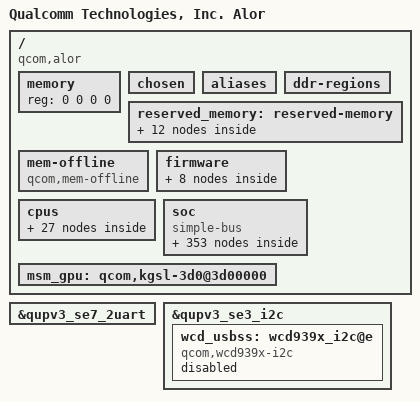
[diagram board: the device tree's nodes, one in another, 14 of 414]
// SPDX-License-Identifier: BSD-3-Clause
/*
 * Copyright (c) Qualcomm Technologies, Inc. and/or its subsidiaries.
 */

#include <dt-bindings/arm/msm/qti-smmu-proxy-dt-ids.h>
#include <dt-bindings/clock/qcom,cambistmclkcc-canoe.h>
#include <dt-bindings/clock/qcom,alor-camcc.h>
#include <dt-bindings/clock/qcom,dispcc-canoe.h>
#include <dt-bindings/clock/qcom,evacc-canoe.h>
#include <dt-bindings/clock/qcom,alor-gcc.h>
#include <dt-bindings/clock/qcom,gpucc-canoe.h>
#include <dt-bindings/clock/qcom,gxclkctl-canoe.h>
#include <dt-bindings/clock/qcom,tcsrcc-canoe.h>
#include <dt-bindings/clock/qcom,videocc-canoe.h>
#include <dt-bindings/clock/qcom,rpmh.h>
#include <dt-bindings/interrupt-controller/arm-gic.h>
#include <dt-bindings/soc/qcom,rpmh-rsc.h>
#include <dt-bindings/interconnect/qcom,icc.h>
#include <dt-bindings/interconnect/qcom,alor.h>
#include <dt-bindings/soc/qcom,ipcc.h>
#include <dt-bindings/mailbox/qcom-ipcc-canoe.h>
#include <dt-bindings/spmi/spmi.h>
#include <dt-bindings/gpio/gpio.h>
#include <dt-bindings/regulator/qcom,rpmh-regulator-levels.h>

/ {
	model = "Qualcomm Technologies, Inc. Alor";
	compatible = "qcom,alor";
	qcom,msm-id = <685 0x10000>;
	interrupt-parent = <&intc>;

	#address-cells = <2>;
	#size-cells = <2>;
	memory { device_type = "memory"; reg = <0 0 0 0>; };


	chosen: chosen {
		bootargs = "loglevel=6 kpti=0 loop.max_part=7 log_buf_len=512K kernel.panic_on_rcu_stall=1 msm_rtb.filter=0x237 rcupdate.rcu_expedited=1 rcu_nocbs=0-7 ftrace_dump_on_oops cpufreq.default_governor=performance printk.console_no_auto_verbose=1 irqaffinity=0-1 swiotlb=0 kasan=off cgroup_disable=pressure cgroup.memory=nokmem,nosocket disable_dma32=on page_poison=on restrict_cma_redirect=false fw_devlink.strict=1 kasan=off can.stats_timer=0 android_arch_task_struct_size=512 pcie_ports=compat sysctl.kernel.sched_pelt_multiplier=4 no-steal-acc pci-msm-drv.pcie_sm_regs=0x1D07000,0x1040,0x1048,0x3000,0x1 androidboot.usbcontroller=a600000.dwc3";
		stdout-path = "/soc/qcom,qupv3_1_geni_se@ac0000/qcom,qup_uart@a9c000:115200n8";
	};

	aliases: aliases {
		mmc1 = &sdhc_2; /* SDC2 SD card slot */
		serial0 = &qupv3_se7_2uart;
		ufshc1 = &ufshc_mem;
		hsuart0 = &qupv3_se14_4uart;
		i2c0 = &qupv3_se0_i2c;
		i2c1 = &qupv3_se1_i2c;
		i2c2 = &qupv3_se2_i2c;
		i2c3 = &qupv3_se3_i2c;
		i2c4 = &qupv3_se4_i2c;
		i2c6 = &qupv3_se6_i2c;
		i2c8 = &qupv3_se8_i2c;
		i2c9 = &qupv3_se9_i2c;
		i2c10 = &qupv3_se10_i2c;
		i2c11 = &qupv3_se11_i2c;
		i2c12 = &qupv3_se12_i2c;
		i2c13 = &qupv3_se13_i2c;
		i2c15 = &qupv3_se15_i2c;
		i2c16 = &qupv3_se16_i2c;
		i2c17 = &qupv3_se17_i2c;
		i2c18 = &qupv3_se18_i2c;
		i2c19 = &qupv3_se19_i2c;
		i2c20 = &qupv3_se20_i2c;
		spi0 = &qupv3_se0_spi;
		spi1 = &qupv3_se1_spi;
		spi2 = &qupv3_se2_spi;
		spi3 = &qupv3_se3_spi;
		spi4 = &qupv3_se4_spi;
		spi6 = &qupv3_se6_spi;
		spi8 = &qupv3_se8_spi;
		spi9 = &qupv3_se9_spi;
		spi10 = &qupv3_se10_spi;
		spi11 = &qupv3_se11_spi;
		spi12 = &qupv3_se12_spi;
		spi13 = &qupv3_se13_spi;
		spi15 = &qupv3_se15_spi;
		spi16 = &qupv3_se16_spi;
		spi17 = &qupv3_se17_spi;
		spi18 = &qupv3_se18_spi;
		spi19 = &qupv3_se19_spi;
		spi20 = &qupv3_se20_spi;
	};

	ddr-regions { };

	reserved_memory: reserved-memory { };

	mem-offline {
		compatible = "qcom,mem-offline";
		offline-sizes = <0x2 0xc0000000 0x1 0x0>;
		granule = <512>;
		qcom,qmp = <&aoss_qmp>;
	};

	firmware: firmware {
		qcom_scm: qcom_scm { };
	};

	cpus {
		#address-cells = <2>;
		#size-cells = <0>;

		CPU0: cpu@0 {
			device_type = "cpu";
			compatible = "arm,armv8";
			reg = <0x0 0x0>;
			enable-method = "psci";
			cpu-idle-states = <&MEDIUM_OFF_C4>;
			power-domains = <&CPU_PD0>;
			power-domain-names = "psci";
			#cooling-cells = <2>;
			clocks = <&pdp_scmi_perf 0>;
			capacity-dmips-mhz = <1024>;
			dynamic-power-coefficient = <100>;
			next-level-cache = <&L2_0>;
			L2_0: l2-cache {
				compatible = "cache";
				cache-level = <2>;
			};
		};

		CPU1: cpu@100 {
			device_type = "cpu";
			compatible = "arm,armv8";
			reg = <0x0 0x100>;
			enable-method = "psci";
			cpu-idle-states = <&MEDIUM_OFF_C4>;
			power-domains = <&CPU_PD1>;
			power-domain-names = "psci";
			#cooling-cells = <2>;
			clocks = <&pdp_scmi_perf 0>;
			capacity-dmips-mhz = <1024>;
			dynamic-power-coefficient = <100>;
			next-level-cache = <&L2_0>;
		};

		CPU2: cpu@200 {
			device_type = "cpu";
			compatible = "arm,armv8";
			reg = <0x0 0x200>;
			enable-method = "psci";
			cpu-idle-states = <&MEDIUM_OFF_C4>;
			power-domains = <&CPU_PD2>;
			power-domain-names = "psci";
			#cooling-cells = <2>;
			clocks = <&pdp_scmi_perf 0>;
			capacity-dmips-mhz = <1024>;
			dynamic-power-coefficient = <100>;
			next-level-cache = <&L2_0>;
		};

		CPU3: cpu@300 {
			device_type = "cpu";
			compatible = "arm,armv8";
			reg = <0x0 0x300>;
			enable-method = "psci";
			cpu-idle-states = <&MEDIUM_OFF_C4>;
			power-domains = <&CPU_PD3>;
			power-domain-names = "psci";
			#cooling-cells = <2>;
			clocks = <&pdp_scmi_perf 0>;
			capacity-dmips-mhz = <1024>;
			dynamic-power-coefficient = <100>;
			next-level-cache = <&L2_0>;
		};

		CPU4: cpu@400 {
			device_type = "cpu";
			compatible = "arm,armv8";
			reg = <0x0 0x400>;
			enable-method = "psci";
			cpu-idle-states = <&MEDIUM_OFF_C4>;
			power-domains = <&CPU_PD4>;
			power-domain-names = "psci";
			#cooling-cells = <2>;
			clocks = <&pdp_scmi_perf 0>;
			capacity-dmips-mhz = <1024>;
			dynamic-power-coefficient = <100>;
			next-level-cache = <&L2_0>;
		};

		CPU5: cpu@500 {
			device_type = "cpu";
			compatible = "arm,armv8";
			reg = <0x0 0x500>;
			enable-method = "psci";
			cpu-idle-states = <&MEDIUM_OFF_C4>;
			power-domains = <&CPU_PD5>;
			power-domain-names = "psci";
			#cooling-cells = <2>;
			clocks = <&pdp_scmi_perf 0>;
			capacity-dmips-mhz = <1024>;
			dynamic-power-coefficient = <100>;
			next-level-cache = <&L2_0>;
		};

		CPU6: cpu@10000 {
			device_type = "cpu";
			compatible = "arm,armv8";
			reg = <0x0 0x10000>;
			enable-method = "psci";
			cpu-idle-states = <&LARGE_OFF_C4>;
			power-domains = <&CPU_PD6>;
			power-domain-names = "psci";
			#cooling-cells = <2>;
			clocks = <&pdp_scmi_perf 1>;
			capacity-dmips-mhz = <1208>;
			dynamic-power-coefficient = <271>;
			next-level-cache = <&L2_6>;
			L2_6: l2-cache {
				compatible = "cache";
				cache-level = <2>;
			};
		};

		CPU7: cpu@10100 {
			device_type = "cpu";
			compatible = "arm,armv8";
			reg = <0x0 0x10100>;
			enable-method = "psci";
			cpu-idle-states = <&LARGE_OFF_C4>;
			power-domains = <&CPU_PD7>;
			power-domain-names = "psci";
			#cooling-cells = <2>;
			clocks = <&pdp_scmi_perf 1>;
			capacity-dmips-mhz = <1208>;
			dynamic-power-coefficient = <271>;
			next-level-cache = <&L2_6>;
		};

		cpu-map {
			cluster0 {
				core0 {
					cpu = <&CPU0>;
				};

				core1 {
					cpu = <&CPU1>;
				};

				core2 {
					cpu = <&CPU2>;
				};

				core3 {
					cpu = <&CPU3>;
				};

				core4 {
					cpu = <&CPU4>;
				};

				core5 {
					cpu = <&CPU5>;
				};
			};

			cluster1 {
				core0 {
					cpu = <&CPU6>;
				};

				core1 {
					cpu = <&CPU7>;
				};
			};
		};

		idle-states {
			entry-method = "psci";

			MEDIUM_OFF_C4: medium-cluster0-c4 { /* C4 */
				compatible = "arm,idle-state";
				idle-state-name = "ret";
				entry-latency-us = <93>;
				exit-latency-us = <129>;
				min-residency-us = <560>;
				arm,psci-suspend-param = <0x00000004>;
			};

			LARGE_OFF_C4: large-cluster1-c4 { /* C4 */
				compatible = "arm,idle-state";
				idle-state-name = "ret";
				entry-latency-us = <172>;
				exit-latency-us = <130>;
				min-residency-us = <686>;
				arm,psci-suspend-param = <0x00000004>;
			};

			MEDIUM_CLUSTER_PWR_DN: medium-cluster-cl5 { /* CL5 */
				compatible = "domain-idle-state";
				entry-latency-us = <2150>;
				exit-latency-us = <1983>;
				min-residency-us = <9144>;
				arm,psci-suspend-param = <0x01000054>;
			};

			LARGE_CLUSTER_PWR_DN: large-cluster-cl5 { /* CL5 */
				compatible = "domain-idle-state";
				entry-latency-us = <2150>;
				exit-latency-us = <1983>;
				min-residency-us = <9144>;
				arm,psci-suspend-param = <0x01000054>;
			};

			APSS_OFF: cluster-ss3 { /* SS3 */
				compatible = "domain-idle-state";
				entry-latency-us = <2800>;
				exit-latency-us = <4400>;
				min-residency-us = <10150>;
				arm,psci-suspend-param = <0x0200B354>;
			};
		};
	};

	soc: soc { };
	msm_gpu: qcom,kgsl-3d0@3d00000 { };
};

#include "alor-reserved-memory.dtsi"
#include "msm-arm-smmu-alor.dtsi"
#include "alor-dma-heaps.dtsi"
#include "alor-pcie.dtsi"

&reserved_memory {
	#address-cells = <2>;
	#size-cells = <2>;
	ranges;

	/* global autoconfigured region for contiguous allocations */
	system_cma: linux,cma {
		compatible = "shared-dma-pool";
		alloc-ranges = <0x0 0x00000000 0x0 0xffffffff>;
		reusable;
		alignment = <0x0 0x400000>;
		size = <0x0 0x2400000>;
		linux,cma-default;
	};

	lcp_dare_pool: lcp_dare_region {
		compatible = "shared-dma-pool";
		reg = <0x8 0x80000000 0x0 0x6000000>;
		reusable;
		alignment = <0x0 0x400000>;
	};

	kinfo_mem: debug_kinfo_region {
		alloc-ranges = <0x0 0x00000000 0xffffffff 0xffffffff>;
		size = <0x0 0x1000>;
		no-map;
	};

	va_md_mem: va_md_mem_region {
		compatible = "shared-dma-pool";
		alloc-ranges = <0x0 0x00000000 0x0 0xffffffff>;
		reusable;
		size = <0 0x1000000>;
	};

	ramoops_mem: ramoops-region {
		alloc-ranges = <0x1 0x00000000 0xfffffffe 0xffffffff>;
		size = <0x0 0x200000>;
		no-map;
	};

	adsp_mem_heap: adsp_heap_region {
		compatible = "shared-dma-pool";
		alloc-ranges = <0x0 0x00000000 0x0 0xffffffff>;
		reusable;
		alignment = <0x0 0x400000>;
		size = <0x0 0xC00000>;
	};

	vm_comm_mem: vm_comm_mem_region {
		compatible = "shared-dma-pool";
		alloc-ranges = <0x0 0x00000000 0x0 0xffffffff>;
		reusable;
		alignment = <0x0 0x400000>;
		size = <0x0 0x800000>;
	};

	hwfence_shbuf: hwfence-shmem {
		no-map;
		reg = <0x0 0xd4e23000 0x0 0x2dd000>;
	};

	non_secure_display_memory: non_secure_display_region {
		compatible = "shared-dma-pool";
		reusable;
		alloc-ranges = <0x0 0x00000000 0x0 0xffffffff>;
		size = <0x0 0xc800000>;
		alignment = <0x0 0x400000>;
	};

	/* cdsp eva shared memory */
	cdsp_eva_mem: cdsp_eva_region {
		compatible = "shared-dma-pool";
		alloc-ranges = <0x0 0x00000000 0x0 0xffffffff>;
		reusable;
		alignment = <0x0 0x400000>;
		size = <0x0 0x400000>;
	};

	qseecom_mem: qseecom_region {
		compatible = "shared-dma-pool";
		alloc-ranges = <0x0 0x00000000 0x0 0xffffffff>;
		reusable;
		alignment = <0x0 0x400000>;
		size = <0x0 0x1400000>;
	};

	qseecom_ta_mem: qseecom_ta_region {
		compatible = "shared-dma-pool";
		alloc-ranges = <0x0 0x00000000 0x0 0xffffffff>;
		reusable;
		alignment = <0x0 0x400000>;
		size = <0x0 0x1400000>;
	};
};

&firmware {
	qcom_scm {
		compatible = "qcom,scm";
		qcom,dload-mode = <&tcsr 0x19000>;
	};

	qcom,sps {
		compatible = "qcom,msm-sps-4k";
		qcom,pipe-attr-ee;
	};

	qcom_smcinvoke {
		compatible = "qcom,smcinvoke";
	};

	qcom_mem_object {
		compatible = "qcom,mem-object";
	};

	qtee_shmbridge {
		compatible = "qcom,tee-shared-memory-bridge";
	};

	qcom,hdcp {
		compatible = "qcom,hdcp";
		qcom,use-smcinvoke = <1>;
	};

	qti,smmu-proxy {
		compatible = "smmu-proxy-sender";
	};

	qcom,seccamtest {
		compatible = "qcom,seccamtest";
		qti,smmu-proxy-cb-id = <QTI_SMMU_PROXY_CAMERA_CB>;
	};
};

&soc {
	#address-cells = <2>;
	#size-cells = <2>;
	ranges = <0 0 0 0 0x10 0>;
	compatible = "simple-bus";

	tlmm: pinctrl@f000000 {
		compatible = "qcom,alor-tlmm";
		reg = <0x0 0xf000000 0x0 0x1000000>;
		interrupts = <GIC_SPI 208 IRQ_TYPE_LEVEL_HIGH>;
		gpio-controller;
		#gpio-cells = <2>;
		interrupt-controller;
		#interrupt-cells = <2>;
		wakeup-parent = <&pdc>;
		qcom,gpios-reserved = <36 37 38 39 46 72 73 74 75 148 149 56 57 58 59>;
	};

	slimbam: bamdma@6c04000 {
		compatible = "qcom,bam-v1.7.0";
		reg = <0x0 0x6c04000 0x0 0x20000>, <0x0 0x6c8f000 0x0 0x1000>;
		reg-names = "bam", "bam_remote_mem";
		interrupts = <0 164 IRQ_TYPE_LEVEL_HIGH>;
		num-channels  = <31>;
		#dma-cells = <1>;
		qcom,controlled-remotely;
		qcom,ee = <1>;
		qcom,num-ees = <2>;
	};

	slim_msm: slim@6c40000 {
		compatible = "qcom,slim-ngd-v1.5.0";
		reg = <0x0 0x6c40000 0x0 0x2c000>, <0x0 0x6c8e000 0x0 0x1000>;
		reg-names = "ctrl", "slimbus_remote_mem";
		interrupts = <0 163 IRQ_TYPE_LEVEL_HIGH>;
		dmas = <&slimbam 3>, <&slimbam 4>;
		dma-names = "rx", "tx";
		#address-cells = <1>;
		#size-cells = <0>;
		status = "disabled";
	};

	intc: interrupt-controller@17000000 {
		compatible = "arm,gic-v3";
		#interrupt-cells = <3>;
		interrupt-controller;
		ranges;
		#redistributor-regions = <1>;
		redistributor-stride = <0x0 0x40000>;
		reg = <0x0 0x17000000 0x0 0x10000>,	/* GICD */
		      <0x0 0x17080000 0x0 0x200000>;	/* GICR * 8 */
		interrupts = <GIC_PPI 9 IRQ_TYPE_LEVEL_HIGH>;

		#address-cells = <1>;
		#size-cells = <1>;
		gic_its: msi-controller@17040000 {
		compatible = "arm,gic-v3-its";
			msi-controller;
			#msi-cells = <1>;
			reg = <0x17040000 0x20000>;
		};
	};

	show_resume_irqs@17000000 {
		compatible = "qcom,show-resume-irqs";
		reg = <0x0 0x17000000 0x0 0x10000>;	/* GICD */
	};

	memtimer: timer@17810000 {
		#address-cells = <1>;
		#size-cells = <1>;
		ranges;
		compatible = "arm,armv7-timer-mem";
		reg = <0x0 0x17810000 0x0 0x1000>;
		clock-frequency = <19200000>;

		frame@17811000 {
			frame-number = <0>;
			interrupts = <GIC_SPI 8 IRQ_TYPE_LEVEL_HIGH>,
				     <GIC_SPI 6 IRQ_TYPE_LEVEL_HIGH>;
			reg = <0x17811000 0x1000>,
			      <0x17812000 0x1000>;
		};

		frame@17813000 {
			frame-number = <1>;
			interrupts = <GIC_SPI 9 IRQ_TYPE_LEVEL_HIGH>;
			reg = <0x17813000 0x1000>;
			status = "disabled";
		};

		frame@17815000 {
			frame-number = <2>;
			interrupts = <GIC_SPI 10 IRQ_TYPE_LEVEL_HIGH>;
			reg = <0x17815000 0x1000>;
			status = "disabled";
		};

		frame@17817000 {
			frame-number = <3>;
			interrupts = <GIC_SPI 11 IRQ_TYPE_LEVEL_HIGH>;
			reg = <0x17817000 0x1000>;
			status = "disabled";
		};

		frame@17819000 {
			frame-number = <4>;
			interrupts = <GIC_SPI 12 IRQ_TYPE_LEVEL_HIGH>;
			reg = <0x17819000 0x1000>;
			status = "disabled";
		};

		frame@1781b000 {
			frame-number = <5>;
			interrupts = <GIC_SPI 13 IRQ_TYPE_LEVEL_HIGH>;
			reg = <0x1781b000 0x1000>;
			status = "disabled";
		};

		frame@1781d000 {
			frame-number = <6>;
			interrupts = <GIC_SPI 14 IRQ_TYPE_LEVEL_HIGH>;
			reg = <0x1781d000 0x1000>;
			status = "disabled";
		};
	};

	wdog: qcom,wdt@17600000 {
		compatible = "qcom,msm-watchdog";
		reg = <0x0 0x17600000 0x0 0x1000>;
		reg-names = "wdt-base";
		interrupts = <GIC_SPI 0 IRQ_TYPE_LEVEL_HIGH>,
			     <GIC_SPI 1 IRQ_TYPE_LEVEL_HIGH>;
		qcom,bark-time = <11000>;
		qcom,pet-time = <9360>;
		qcom,ipi-ping;
		qcom,wakeup-enable;
	};

	arch_timer: timer {
		compatible = "arm,armv8-timer";
		interrupts = <GIC_PPI 13 (GIC_CPU_MASK_SIMPLE(8) | IRQ_TYPE_LEVEL_LOW)>,
			     <GIC_PPI 14 (GIC_CPU_MASK_SIMPLE(8) | IRQ_TYPE_LEVEL_LOW)>,
			     <GIC_PPI 11 (GIC_CPU_MASK_SIMPLE(8) | IRQ_TYPE_LEVEL_LOW)>,
			     <GIC_PPI 10 (GIC_CPU_MASK_SIMPLE(8) | IRQ_TYPE_LEVEL_LOW)>;
		clock-frequency = <19200000>;
	};

	pcie_crm_hw_0_bcm_voter: bcm_voter@0 {
		compatible = "qcom,bcm-voter";
		qcom,crm-name = "pcie_crm";
		qcom,crm-client-idx = <0>;
		qcom,crm-pwr-states = <5>;
	};

	disp_crm_hw_0_bcm_voter: bcm_voter@1 {
		compatible = "qcom,bcm-voter";
		qcom,crm-name = "disp_crm";
		qcom,crm-client-idx = <0>;
		qcom,crm-pwr-states = <2>;
	};

	disp_crm_hw_1_bcm_voter: bcm_voter@2 {
		compatible = "qcom,bcm-voter";
		qcom,crm-name = "disp_crm";
		qcom,crm-client-idx = <1>;
		qcom,crm-pwr-states = <2>;
	};

	disp_crm_hw_2_bcm_voter: bcm_voter@3 {
		compatible = "qcom,bcm-voter";
		qcom,crm-name = "disp_crm";
		qcom,crm-client-idx = <2>;
		qcom,crm-pwr-states = <2>;
	};

	disp_crm_hw_3_bcm_voter: bcm_voter@4 {
		compatible = "qcom,bcm-voter";
		qcom,crm-name = "disp_crm";
		qcom,crm-client-idx = <3>;
		qcom,crm-pwr-states = <2>;
	};

	disp_crm_hw_4_bcm_voter: bcm_voter@5 {
		compatible = "qcom,bcm-voter";
		qcom,crm-name = "disp_crm";
		qcom,crm-client-idx = <4>;
		qcom,crm-pwr-states = <2>;
	};

	disp_crm_hw_5_bcm_voter: bcm_voter@6 {
		compatible = "qcom,bcm-voter";
		qcom,crm-name = "disp_crm";
		qcom,crm-client-idx = <5>;
		qcom,crm-pwr-states = <2>;
	};

	disp_crm_hw_6_bcm_voter: bcm_voter@7 {
		compatible = "qcom,bcm-voter";
		qcom,crm-name = "disp_crm";
		qcom,crm-client-idx = <6>;
		qcom,crm-pwr-states = <2>;
	};

	disp_crm_hw_7_bcm_voter: bcm_voter@8 {
		compatible = "qcom,bcm-voter";
		qcom,crm-name = "disp_crm";
		qcom,crm-client-idx = <7>;
		qcom,crm-pwr-states = <2>;
	};

	disp_crm_hw_8_bcm_voter: bcm_voter@9 {
		compatible = "qcom,bcm-voter";
		qcom,crm-name = "disp_crm";
		qcom,crm-client-idx = <8>;
		qcom,crm-pwr-states = <2>;
	};

	disp_crm_sw_0_bcm_voter: bcm_voter@10 {
		compatible = "qcom,bcm-voter";
		qcom,crm-name = "disp_crm";
		qcom,crm-sw-client;
		qcom,crm-client-idx = <1>;
		qcom,crm-pwr-states = <1>;
	};

	clk_virt: interconnect@0 {
		compatible = "qcom,alor-clk_virt";
		#interconnect-cells = <1>;
		qcom,bcm-voter-names = "hlos",
				       "pcie_crm_hw_0";
		qcom,bcm-voters = <&apps_bcm_voter>,
				  <&pcie_crm_hw_0_bcm_voter>;
	};

	mc_virt: interconnect@1 {
		compatible = "qcom,alor-mc_virt";
		#interconnect-cells = <1>;
		qcom,bcm-voter-names = "hlos",
				       "cam_ife_0",
				       "cam_ife_1",
				       "cam_ife_2",
				       "pcie_crm_hw_0",
				       "disp_crm_hw_0",
				       "disp_crm_hw_1",
				       "disp_crm_hw_2",
				       "disp_crm_hw_3",
				       "disp_crm_hw_4",
				       "disp_crm_hw_5",
				       "disp_crm_hw_6",
				       "disp_crm_hw_7",
				       "disp_crm_hw_8",
				       "disp_crm_sw_0";
		qcom,bcm-voters = <&apps_bcm_voter>,
				  <&cam_bcm_voter0>,
				  <&cam_bcm_voter1>,
				  <&cam_bcm_voter2>,
				  <&pcie_crm_hw_0_bcm_voter>,
				  <&disp_crm_hw_0_bcm_voter>,
				  <&disp_crm_hw_1_bcm_voter>,
				  <&disp_crm_hw_2_bcm_voter>,
				  <&disp_crm_hw_3_bcm_voter>,
				  <&disp_crm_hw_4_bcm_voter>,
				  <&disp_crm_hw_5_bcm_voter>,
				  <&disp_crm_hw_6_bcm_voter>,
				  <&disp_crm_hw_7_bcm_voter>,
				  <&disp_crm_hw_8_bcm_voter>,
				  <&disp_crm_sw_0_bcm_voter>;
	};

	aggre1_noc: interconnect@16e0000 {
		compatible = "qcom,alor-aggre1_noc";
		reg = <0x0 0x16e0000 0x0 0x16400>;
		#interconnect-cells = <1>;
		clocks = <&gcc GCC_AGGRE_UFS_PHY_AXI_CLK>,
			 <&gcc GCC_AGGRE_USB3_PRIM_AXI_CLK>;
		qcom,bcm-voter-names = "hlos";
		qcom,bcm-voters = <&apps_bcm_voter>;
	};

	aggre2_noc: interconnect@1700000 {
		compatible = "qcom,alor-aggre2_noc";
		reg = <0x0 0x1700000 0x0 0x22400>;
		#interconnect-cells = <1>;
		clocks = <&rpmhcc RPMH_IPA_CLK>;
		qcom,bcm-voter-names = "hlos";
		qcom,bcm-voters = <&apps_bcm_voter>;
	};

	config_noc: interconnect@1600000 {
		compatible = "qcom,alor-cnoc_cfg";
		reg = <0x0 0x1600000 0x0 0x9200>;
		#interconnect-cells = <1>;
		qcom,bcm-voter-names = "hlos";
		qcom,bcm-voters = <&apps_bcm_voter>;
	};

	cnoc_main: interconnect@1500000 {
		compatible = "qcom,alor-cnoc_main";
		reg = <0x0 0x1500000 0x0 0x1a080>;
		#interconnect-cells = <1>;
		qcom,bcm-voter-names = "hlos";
		qcom,bcm-voters = <&apps_bcm_voter>;
	};

	gem_noc: interconnect@31100000 {
		compatible = "qcom,alor-gem_noc";
		reg = <0x0 0x31100000 0x0 0x153080>;
		#interconnect-cells = <1>;
		qcom,bcm-voter-names = "hlos",
				       "cam_ife_0",
				       "cam_ife_1",
				       "cam_ife_2",
				       "pcie_crm_hw_0",
				       "disp_crm_hw_0",
				       "disp_crm_hw_1",
				       "disp_crm_hw_2",
				       "disp_crm_hw_3",
				       "disp_crm_hw_4",
				       "disp_crm_hw_5",
				       "disp_crm_hw_6",
				       "disp_crm_hw_7",
				       "disp_crm_hw_8",
				       "disp_crm_sw_0";
		qcom,bcm-voters = <&apps_bcm_voter>,
				  <&cam_bcm_voter0>,
				  <&cam_bcm_voter1>,
				  <&cam_bcm_voter2>,
				  <&pcie_crm_hw_0_bcm_voter>,
				  <&disp_crm_hw_0_bcm_voter>,
				  <&disp_crm_hw_1_bcm_voter>,
				  <&disp_crm_hw_2_bcm_voter>,
				  <&disp_crm_hw_3_bcm_voter>,
				  <&disp_crm_hw_4_bcm_voter>,
				  <&disp_crm_hw_5_bcm_voter>,
				  <&disp_crm_hw_6_bcm_voter>,
				  <&disp_crm_hw_7_bcm_voter>,
				  <&disp_crm_hw_8_bcm_voter>,
				  <&disp_crm_sw_0_bcm_voter>;
	};

	lpass_ag_noc: interconnect@7f40000 {
		compatible = "qcom,alor-lpass_ag_noc";
		reg = <0x0 0x7f40000 0x0 0xe080>;
		#interconnect-cells = <1>;
		qcom,bcm-voter-names = "hlos";
		qcom,bcm-voters = <&apps_bcm_voter>;
	};

	lpass_lpiaon_noc: interconnect@7400000 {
		compatible = "qcom,alor-lpass_lpiaon_noc";
		reg = <0x0 0x7400000 0x0 0x19080>;
		#interconnect-cells = <1>;
		qcom,bcm-voter-names = "hlos";
		qcom,bcm-voters = <&apps_bcm_voter>;
	};

	lpass_lpicx_noc: interconnect@7420000 {
		compatible = "qcom,alor-lpass_lpicx_noc";
		reg = <0x0 0x7420000 0x0 0x44080>;
		#interconnect-cells = <1>;
		qcom,bcm-voter-names = "hlos";
		qcom,bcm-voters = <&apps_bcm_voter>;
	};

	mmss_noc: interconnect@1780000 {
		compatible = "qcom,alor-mmss_noc";
		reg = <0x0 0x1780000 0x0 0x7d400>;
		#interconnect-cells = <1>;
		qcom,bcm-voter-names = "hlos",
				       "cam_ife_0",
				       "cam_ife_1",
				       "cam_ife_2",
				       "disp_crm_hw_0",
				       "disp_crm_hw_1",
				       "disp_crm_hw_2",
				       "disp_crm_hw_3",
				       "disp_crm_hw_4",
				       "disp_crm_hw_5",
				       "disp_crm_hw_6",
				       "disp_crm_hw_7",
				       "disp_crm_hw_8",
				       "disp_crm_sw_0";
		qcom,bcm-voters = <&apps_bcm_voter>,
				  <&cam_bcm_voter0>,
				  <&cam_bcm_voter1>,
				  <&cam_bcm_voter2>,
				  <&disp_crm_hw_0_bcm_voter>,
				  <&disp_crm_hw_1_bcm_voter>,
				  <&disp_crm_hw_2_bcm_voter>,
				  <&disp_crm_hw_3_bcm_voter>,
				  <&disp_crm_hw_4_bcm_voter>,
				  <&disp_crm_hw_5_bcm_voter>,
				  <&disp_crm_hw_6_bcm_voter>,
				  <&disp_crm_hw_7_bcm_voter>,
				  <&disp_crm_hw_8_bcm_voter>,
				  <&disp_crm_sw_0_bcm_voter>;
	};

	nsp_noc: interconnect@260c0000 {
		compatible = "qcom,alor-nsp_noc";
		reg = <0x0 0x260c0000 0x0 0x1c080>;
		#interconnect-cells = <1>;
		qcom,bcm-voter-names = "hlos";
		qcom,bcm-voters = <&apps_bcm_voter>;
	};

	pcie_anoc: interconnect@16c0000 {
		compatible = "qcom,alor-pcie_anoc";
		reg = <0x0 0x16c0000 0x0 0x11400>;
		#interconnect-cells = <1>;
		clocks = <&gcc GCC_AGGRE_NOC_PCIE_AXI_CLK>,
			 <&gcc GCC_CFG_NOC_PCIE_ANOC_AHB_CLK>;
		qcom,bcm-voter-names = "hlos",
				       "pcie_crm_hw_0";
		qcom,bcm-voters = <&apps_bcm_voter>,
				  <&pcie_crm_hw_0_bcm_voter>;
	};

	system_noc: interconnect@1680000 {
		compatible = "qcom,alor-system_noc";
		reg = <0x0 0x1680000 0x0 0x1f080>;
		#interconnect-cells = <1>;
		qcom,bcm-voter-names = "hlos";
		qcom,bcm-voters = <&apps_bcm_voter>;
	};

	ipcc_mproc: qcom,ipcc@1106000 {
		compatible = "qcom,ipcc";
		reg = <0x0 0x1106000 0x0 0x1000>;
		interrupts = <GIC_SPI 246 IRQ_TYPE_LEVEL_HIGH>;
		interrupt-controller;
		#interrupt-cells = <3>;
		#mbox-cells = <2>;
	};

	qcom_tzlog: tz-log@14680720 {
		compatible = "qcom,tz-log";
		reg = <0x0 0x14680720 0x0 0x3000>;
		qcom,hyplog-enabled;
		hyplog-address-offset = <0x410>;
		hyplog-size-offset = <0x414>;
		tmecrashdump-address-offset = <0x81CA0000>;
	};

	eud: qcom,msm-eud@88e0000 {
		compatible = "qcom,msm-eud";
		interrupt-names = "eud_irq";
		interrupt-parent = <&pdc>;
		interrupts = <11 IRQ_TYPE_LEVEL_HIGH>;
		reg = <0x0 0x88e0000 0x0 0x2000>,
			<0x0 0x88e2000 0x0 0x1000>;
		reg-names = "eud_base", "eud_mode_mgr2";
		qcom,secure-eud-en;
		qcom,eud-utmi-delay = /bits/ 16 <255>;
		status = "ok";
	};

	cache-controller@31800000 {
		compatible = "qcom,alor-llcc";
		reg = <0x0 0x31800000 0x0 0x200000>, <0x0 0x32800000 0x0 0x200000>,
			<0x0 0x31C00000 0x0 0x200000>, <0x0 0x32C00000 0x0 0x200000>,
			<0x0 0x34800000 0x0 0x200000>, <0x0 0x34C00000 0x0 0x200000>;
		reg-names = "llcc0_base", "llcc1_base", "llcc2_base",
			"llcc3_base", "llcc_broadcast_or_base",
			"llcc_broadcast_and_base";
		interrupts = <GIC_SPI 266 IRQ_TYPE_LEVEL_HIGH>;
		cap-based-alloc-and-pwr-collapse;
	};

	gic-interrupt-router {
		compatible = "qcom,gic-intr-routing";
		/* keep a few m cores in class0 only to avoid wakeup of l cores */
		qcom,gic-class0-cpus = <&CPU0 &CPU1>;
		/* keep other cores in class1 */
		qcom,gic-class1-cpus = <&CPU2 &CPU3 &CPU4 &CPU5 &CPU6 &CPU7>;
		qcom,gic-cpulist = <&CPU0 &CPU1 &CPU2 &CPU3 &CPU4 &CPU5 &CPU6 &CPU7>;
		qcom,gic-runtime-cpu-class-en;
	};

	qcom,secure-buffer {
		compatible = "qcom,secure-buffer";
		qcom,vmid-cp-camera-preview-ro;
	};

	qcom,mem-buf {
		compatible = "qcom,mem-buf";
		qcom,mem-buf-capabilities = "supplier";
		qcom,vmid = <3>;
	};

	qcom,mem-buf-msgq {
		compatible = "qcom,mem-buf-msgq";
		qcom,msgq-names = "trusted_vm", "oem_vm";
	};

	psci {
		compatible = "arm,psci-1.0";
		method = "smc";

		CPU_PD0: cpu-pd0 {
			#power-domain-cells = <0>;
			power-domains = <&CLUSTER_PD0>;
		};

		CPU_PD1: cpu-pd1 {
			#power-domain-cells = <0>;
			power-domains = <&CLUSTER_PD0>;
		};

		CPU_PD2: cpu-pd2 {
			#power-domain-cells = <0>;
			power-domains = <&CLUSTER_PD0>;
		};

		CPU_PD3: cpu-pd3 {
			#power-domain-cells = <0>;
			power-domains = <&CLUSTER_PD0>;
		};

		CPU_PD4: cpu-pd4 {
			#power-domain-cells = <0>;
			power-domains = <&CLUSTER_PD0>;
		};

		CPU_PD5: cpu-pd5 {
			#power-domain-cells = <0>;
			power-domains = <&CLUSTER_PD0>;
		};

		CPU_PD6: cpu-pd6 {
			#power-domain-cells = <0>;
			power-domains = <&CLUSTER_PD1>;
		};

		CPU_PD7: cpu-pd7 {
			#power-domain-cells = <0>;
			power-domains = <&CLUSTER_PD1>;
		};

		CLUSTER_PD0: cluster-pd0 {
			#power-domain-cells = <0>;
			power-domains = <&CLUSTER_PD2>;
			domain-idle-states = <&MEDIUM_CLUSTER_PWR_DN>;
		};

		CLUSTER_PD1: cluster-pd1 {
			#power-domain-cells = <0>;
			power-domains = <&CLUSTER_PD2>;
			domain-idle-states = <&LARGE_CLUSTER_PWR_DN>;
		};

		CLUSTER_PD2: cluster-pd2 {
			#power-domain-cells = <0>;
			domain-idle-states = <&APSS_OFF>;
		};
	};

	disp_crm: crm@9bc3000 {
		label = "disp_crm";
		compatible = "qcom,disp-crm-v3";
		reg = <0x0 0x9bc3000 0x0 0x9000>, <0x0 0x9bcc000 0x0 0x400>, <0x0 0x9bcc400 0x0 0x400>,
		      <0x0 0x9bcc800 0x0 0x2000>, <0x0 0x9bce800 0x0 0x600>, <0x0 0x9bcee00 0x0 0x200>;
		reg-names = "base", "crm_b", "crm_b_pt", "crm_c", "crm_v", "common";
		interrupts = <GIC_SPI 812 IRQ_TYPE_EDGE_RISING>,
			     <GIC_SPI 813 IRQ_TYPE_EDGE_RISING>,
			     <GIC_SPI 814 IRQ_TYPE_EDGE_RISING>,
			     <GIC_SPI 815 IRQ_TYPE_EDGE_RISING>,
			     <GIC_SPI 816 IRQ_TYPE_EDGE_RISING>,
			     <GIC_SPI 817 IRQ_TYPE_EDGE_RISING>;
		interrupt-names = "disp_crm_drv0",
				  "disp_crm_drv1",
				  "disp_crm_drv2",
				  "disp_crm_drv3",
				  "disp_crm_drv4",
				  "disp_crm_drv5";
		clocks = <&dispcc DISP_CC_MDSS_AHB_CLK>;
		qcom,hw-drv-ids = <0 1 2 3 4 5 6 7 8>;
		qcom,sw-drv-ids = <1>;
	};

	cam_crm: crm@9548000 {
		label = "cam_crm";
		compatible = "qcom,cam-crm-v3";
		reg = <0x0 0x9548000 0x0 0x1e00>, <0x0 0x9549e00 0x0 0x400>, <0x0 0x954a200 0x0 0x400>,
		      <0x0 0x954a600 0x0 0x2000>, <0x0 0x954c600 0x0 0x600>, <0x0 0x954cc00 0x0 0x200>;
		reg-names = "base", "crm_b", "crm_b_pt", "crm_c", "crm_v", "common";
		interrupts = <GIC_SPI 121 IRQ_TYPE_EDGE_RISING>;
		interrupt-names = "cam_crm_drv0";
		clocks = <&camcc CAM_CC_DRV_AHB_CLK>;
		qcom,hw-drv-ids = <0 1 2>;
		qcom,sw-drv-ids = <0>;
	};

	pcie_crm: crm@1d01000 {
		label = "pcie_crm";
		compatible = "qcom,pcie-crm-v3";
		reg = <0x0 0x1d01000 0x0 0x2000>, <0x0 0x1d03000 0x0 0x400>, <0x0 0x1d03400 0x0 0x400>,
		      <0x0 0x1d03800 0x0 0x2000>, <0x0 0x1d05800 0x0 0x600>, <0x0 0x1d05e00 0x0 0x200>;
		reg-names = "base", "crm_b", "crm_b_pt", "crm_c", "crm_v", "common";
		interrupts = <GIC_SPI 641 IRQ_TYPE_EDGE_RISING>;
		interrupt-names = "pcie_crm_drv0";
		clocks = <&pcie_0_pipe_clk>;
		qcom,hw-drv-ids = <0 1>;
		qcom,sw-drv-ids = <0>;
	};

	pcie_pdc: pdc@b370000 {
		compatible = "qcom,alor-pcie-pdc", "qcom,pcie-pdc";
		reg = <0x0 0xb370000 0x0 0x10000>;
	};

	google,debug-kinfo {
		compatible = "google,debug-kinfo";
		memory-region = <&kinfo_mem>;
	};

	mini_dump_mode {
		compatible = "qcom,minidump";
		status = "ok";
	};

	va_mini_dump {
		compatible = "qcom,va-minidump";
		memory-region = <&va_md_mem>;
		status = "ok";
	};

	qcom_ramoops {
		compatible = "qcom,ramoops";
		memory-region = <&ramoops_mem>;
		pmsg-size = <0x200000>;
		mem-type = <2>;
	};

	qcom,mpm2-sleep-counter@c221000 {
		compatible = "qcom,mpm2-sleep-counter";
		reg = <0x0 0xc221000 0x0 0x1000>;
		clock-frequency = <32768>;
	};

	tcsr: syscon@1fc0000 {
		compatible = "syscon";
		reg = <0x0 0x1fc0000 0x0 0x30000>;
	};

	tcsr_mutex_block: syscon@1f40000 {
		compatible = "syscon";
		reg = <0x0 0x1f40000 0x0 0x20000>;
	};

	tcsr_mutex: hwlock {
		compatible = "qcom,tcsr-mutex";
		syscon = <&tcsr_mutex_block 0 0x1000>;
		#hwlock-cells = <1>;
	};

	aoss_qmp: power-controller@c300000 {
		compatible = "qcom,aoss-qmp";
		reg = <0x0 0xc300000 0x0 0x400>;
		interrupt-parent = <&ipcc_mproc>;
		interrupts = <IPCC_MPROC_AOP
			      IPCC_MPROC_SIGNAL_GLINK_QMP
			      IRQ_TYPE_EDGE_RISING>;
		mboxes = <&ipcc_mproc IPCC_MPROC_AOP
			  IPCC_MPROC_SIGNAL_GLINK_QMP>;

		#power-domain-cells = <1>;
		#clock-cells = <0>;
	};

	qmp_tme: qcom,qmp-tme {
		compatible = "qcom,qmp-mbox";
		qcom,remote-pid = <14>;
		mboxes = <&ipcc_mproc IPCC_MPROC_TME
			  IPCC_MPROC_SIGNAL_GLINK_QMP>;
		mbox-names = "tme_qmp";
		interrupt-parent = <&ipcc_mproc>;
		interrupts = <IPCC_MPROC_TME
			      IPCC_MPROC_SIGNAL_GLINK_QMP
			      IRQ_TYPE_EDGE_RISING>;

		label = "tme";
		qcom,early-boot;
		priority = <0>;
		mbox-desc-offset = <0x0>;
		#mbox-cells = <1>;
	};

	qcom,tmecom-qmp-client {
		compatible = "qcom,tmecom-qmp-client";
		mboxes = <&qmp_tme 0>;
		mbox-names = "tmecom";
		label = "tmecom";
		depends-on-supply = <&qmp_tme>;
	};

	qcom,smp2p-adsp {
		compatible = "qcom,smp2p";
		qcom,smem = <443>, <429>;
		interrupt-parent = <&ipcc_mproc>;
		interrupts = <IPCC_MPROC_LPASS IPCC_MPROC_SIGNAL_SMP2P
			      IRQ_TYPE_EDGE_RISING>;
		mboxes = <&ipcc_mproc IPCC_MPROC_LPASS
			  IPCC_MPROC_SIGNAL_SMP2P>;
		qcom,local-pid = <0>;
		qcom,remote-pid = <2>;

		adsp_smp2p_out: master-kernel {
			qcom,entry-name = "master-kernel";
			#qcom,smem-state-cells = <1>;
		};

		adsp_smp2p_in: slave-kernel {
			qcom,entry-name = "slave-kernel";
			interrupt-controller;
			#interrupt-cells = <2>;
		};

		sleepstate_smp2p_out: sleepstate-out {
			qcom,entry-name = "sleepstate";
			#qcom,smem-state-cells = <1>;
		};

		sleepstate_smp2p_in: qcom,sleepstate-in {
			qcom,entry-name = "sleepstate_see";
			interrupt-controller;
			#interrupt-cells = <2>;
		};

		smp2p_rdbg2_out: qcom,smp2p-rdbg2-out {
			qcom,entry-name = "rdbg";
			#qcom,smem-state-cells = <1>;
		};

		smp2p_rdbg2_in: qcom,smp2p-rdbg2-in {
			qcom,entry-name = "rdbg";
			interrupt-controller;
			#interrupt-cells = <2>;
		};
	};

	qcom,smp2p-cdsp {
		compatible = "qcom,smp2p";
		qcom,smem = <94>, <432>;
		interrupt-parent = <&ipcc_mproc>;
		interrupts = <IPCC_MPROC_CDSP IPCC_MPROC_SIGNAL_SMP2P
			      IRQ_TYPE_EDGE_RISING>;
		mboxes = <&ipcc_mproc IPCC_MPROC_CDSP IPCC_MPROC_SIGNAL_SMP2P>;
		qcom,local-pid = <0>;
		qcom,remote-pid = <5>;

		cdsp_smp2p_out: master-kernel {
			qcom,entry-name = "master-kernel";
			#qcom,smem-state-cells = <1>;
		};

		cdsp_smp2p_in: slave-kernel {
			qcom,entry-name = "slave-kernel";
			interrupt-controller;
			#interrupt-cells = <2>;
		};

		smp2p_rdbg5_out: qcom,smp2p-rdbg5-out {
			qcom,entry-name = "rdbg";
			#qcom,smem-state-cells = <1>;
		};

		smp2p_rdbg5_in: qcom,smp2p-rdbg5-in {
			qcom,entry-name = "rdbg";
			interrupt-controller;
			#interrupt-cells = <2>;
		};
	};

	qcom,smp2p-modem {
		compatible = "qcom,smp2p";
		qcom,smem = <435>, <428>;
		interrupt-parent = <&ipcc_mproc>;
		interrupts = <IPCC_MPROC_MPSS IPCC_MPROC_SIGNAL_SMP2P
			      IRQ_TYPE_EDGE_RISING>;
		mboxes = <&ipcc_mproc IPCC_MPROC_MPSS IPCC_MPROC_SIGNAL_SMP2P>;
		qcom,local-pid = <0>;
		qcom,remote-pid = <1>;

		modem_smp2p_out: master-kernel {
			qcom,entry-name = "master-kernel";
			#qcom,smem-state-cells = <1>;
		};

		modem_smp2p_in: slave-kernel {
			qcom,entry-name = "slave-kernel";
			interrupt-controller;
			#interrupt-cells = <2>;
		};

		smp2p_ipa_1_out: qcom,smp2p-ipa-1-out {
			qcom,entry-name = "ipa";
			#qcom,smem-state-cells = <1>;
		};

		/* ipa - inbound entry from mss */
		smp2p_ipa_1_in: qcom,smp2p-ipa-1-in {
			qcom,entry-name = "ipa";
			interrupt-controller;
			#interrupt-cells = <2>;
		};

		smp2p_smem_mailbox_1_out: qcom,smp2p-smem-mailbox-1-out {
			qcom,entry-name = "smem-mailbox";
			#qcom,smem-state-cells = <1>;
		};

		smp2p_smem_mailbox_1_in: qcom,smp2p-smem-mailbox-1-in {
			qcom,entry-name = "smem-mailbox";
			interrupt-controller;
			#interrupt-cells = <2>;
		};
	};

	qcom,smp2p-soccp {
		compatible = "qcom,smp2p";
		qcom,smem = <617>, <616>;
		interrupt-parent = <&ipcc_mproc>;
		interrupts = <IPCC_MPROC_SOCCP IPCC_MPROC_SIGNAL_SMP2P
			      IRQ_TYPE_EDGE_RISING>;
		mboxes = <&ipcc_mproc IPCC_MPROC_SOCCP IPCC_MPROC_SIGNAL_SMP2P>;
		qcom,local-pid = <0>;
		qcom,remote-pid = <19>;

		soccp_smp2p_out: master-kernel {
			qcom,entry-name = "master-kernel";
			#qcom,smem-state-cells = <1>;
		};

		soccp_smp2p_in: slave-kernel {
			qcom,entry-name = "slave-kernel";
			interrupt-controller;
			#interrupt-cells = <2>;
		};
	};

	qcom,smp2p-dcp {
		compatible = "qcom,smp2p";
		qcom,smem = <617>, <616>;
		interrupt-parent = <&ipcc_mproc>;
		interrupts = <IPCC_MPROC_DCP IPCC_MPROC_SIGNAL_SMP2P
			      IRQ_TYPE_EDGE_RISING>;
		mboxes = <&ipcc_mproc IPCC_MPROC_DCP IPCC_MPROC_SIGNAL_SMP2P>;
		qcom,local-pid = <0>;
		qcom,remote-pid = <22>;

		dcp_smp2p_out: master-kernel {
			qcom,entry-name = "master-kernel";
			#qcom,smem-state-cells = <1>;
		};

		dcp_smp2p_in: slave-kernel {
			qcom,entry-name = "slave-kernel";
			interrupt-controller;
			#interrupt-cells = <2>;
		};
	};

	qcom,smp2p-wpss {
		compatible = "qcom,smp2p";
		qcom,smem = <617>, <616>;
		interrupt-parent = <&ipcc_mproc>;
		interrupts = <IPCC_MPROC_WPSS IPCC_MPROC_SIGNAL_SMP2P
			      IRQ_TYPE_EDGE_RISING>;
		mboxes = <&ipcc_mproc IPCC_MPROC_WPSS IPCC_MPROC_SIGNAL_SMP2P>;
		qcom,local-pid = <0>;
		qcom,remote-pid = <13>;

		wpss_smp2p_out: master-kernel {
			qcom,entry-name = "master-kernel";
			#qcom,smem-state-cells = <1>;
		};

		wpss_smp2p_in: slave-kernel {
			qcom,entry-name = "slave-kernel";
			interrupt-controller;
			#interrupt-cells = <2>;
		};
	};

	qcom,smp2p_sleepstate {
		compatible = "qcom,smp2p-sleepstate";
		qcom,smem-states = <&sleepstate_smp2p_out 0>;
		interrupt-parent = <&sleepstate_smp2p_in>;
		interrupts = <0 0>;
		interrupt-names = "smp2p-sleepstate-in";
	};

	qcom,msm-imem@14680000 {
		compatible = "qcom,msm-imem";
		reg = <0x0 0x14680000 0x0 0x1000>;
		ranges = <0x0 0x0 0x14680000 0x1000>;
		#address-cells = <1>;
		#size-cells = <1>;

		mem_dump_table@10 {
			compatible = "qcom,msm-imem-mem_dump_table";
			reg = <0x10 0x8>;
		};

		restart_reason@65c {
			compatible = "qcom,msm-imem-restart_reason";
			reg = <0x65c 0x4>;
		};

		dload_type@1c {
			compatible = "qcom,msm-imem-dload-type";
			reg = <0x1c 0x4>;
		};

		boot_stats@6b0 {
			compatible = "qcom,msm-imem-boot_stats";
			reg = <0x6b0 0x20>;
		};

		kaslr_offset@6d0 {
			compatible = "qcom,msm-imem-kaslr_offset";
			reg = <0x6d0 0xc>;
		};

		pil@94c {
			compatible = "qcom,pil-reloc-info";
			reg = <0x94c 0xc8>;
		};

		pil@6dc {
			compatible = "qcom,msm-imem-pil-disable-timeout";
			reg = <0x6dc 0x4>;
		};

		diag_dload@c8 {
			compatible = "qcom,msm-imem-diag-dload";
			reg = <0xc8 0xc8>;
		};

		modem_dsm@c98 {
			compatible = "qcom,msm-imem-mss-dsm";
			reg = <0xc98 0x10>;
		};

		sys_dbg@af8 {
			compatible = "qcom,msm-imem-gpu-dump-skip";
			reg = <0xb0c 0x4>;
		};
	};

	qcom,memshare {
		compatible = "qcom,memshare";

		qcom,client_1 {
			compatible = "qcom,memshare-peripheral";
			qcom,peripheral-size = <0x0>;
			qcom,client-id = <0>;
			qcom,allocate-boot-time;
			label = "modem";
		};

		qcom,client_2 {
			compatible = "qcom,memshare-peripheral";
			qcom,peripheral-size = <0x0>;
			qcom,client-id = <2>;
			label = "modem";
		};

		qcom,client_3 {
			compatible = "qcom,memshare-peripheral";
			qcom,peripheral-size = <0x500000>;
			qcom,client-id = <1>;
			qcom,allocate-on-request;
			label = "modem";
		};

		qcom,client_ims_1 {
			compatible = "qcom,memshare-peripheral";
			qcom,peripheral-size = <0x100000>;
			qcom,client-id = <7>;
			qcom,allocate-on-request;
			qcom,shared;
			label = "modem";
		};

		qcom,client_ims_2 {
			compatible = "qcom,memshare-peripheral";
			qcom,peripheral-size = <0x100000>;
			qcom,client-id = <8>;
			qcom,allocate-on-request;
			qcom,shared;
			label = "modem";
		};
	};

	cpu_pmu: cpu-pmu {
		compatible = "arm,armv8-pmuv3";
		interrupts = <GIC_PPI 7 IRQ_TYPE_LEVEL_HIGH>;
	};

	vendor_hooks: qcom,cpu-vendor-hooks {
		compatible = "qcom,cpu-vendor-hooks";
	};

	logbuf: qcom,logbuf-vendor-hooks {
		compatible = "qcom,logbuf-vendor-hooks";
	};

	qfprom: qfprom@221c8000 {
		compatible = "qcom,alor-qfprom", "qcom,qfprom";
		reg = <0x0 0x221c8000 0x0 0x1000>;
		#address-cells = <1>;
		#size-cells = <1>;
		read-only;
		ranges;
	};

	cnss_audio_iommu_group0: cnss_audio_iommu_group0 {
		qcom,iommu-msi-size = <0x1000>;
		qcom,iommu-geometry = <0x0 0x18000000 0x0 0x98010000>;
		qcom,iommu-dma = "fastmap";
		qcom,iommu-pagetable = "coherent";
		qcom,iommu-faults = "stall-disable", "HUPCF", "non-fatal";
	};

	wpss_pas: remoteproc-wpss@99f00000 {
		compatible = "qcom,alor-wpss-pas";
		reg = <0x0 0x99f00000 0x0 0x10000>;
		status = "ok";

		memory-region = <&wpss_mem>;

		firmware-name = "wcn7750/wpss.mdt";

		clocks = <&rpmhcc RPMH_CXO_CLK>;
		clock-names = "xo";

		cx-supply = <&VDD_CX_LEVEL>;
		cx-uV-uA = <RPMH_REGULATOR_LEVEL_TURBO 100000>;
		mx-supply = <&VDD_MX_LEVEL>;
		mx-uV-uA = <RPMH_REGULATOR_LEVEL_TURBO 100000>;
		reg-names = "cx","mx";

		qcom,qmp = <&aoss_qmp>;

		/* Inputs from wpss */
		interrupts-extended = <&intc GIC_SPI 87 IRQ_TYPE_EDGE_RISING>,
				      <&wpss_smp2p_in 0 0>,
				      <&wpss_smp2p_in 2 0>,
				      <&wpss_smp2p_in 1 0>,
				      <&wpss_smp2p_in 3 0>,
				      <&wpss_smp2p_in 7 0>;

		interrupt-names = "wdog",
				   "fatal",
				   "handover",
				   "ready",
				   "stop-ack",
				   "shutdown-ack";

		/* Outputs to wpss */
		qcom,smem-states = <&wpss_smp2p_out 0>;
		qcom,smem-state-names = "stop";

		glink-edge {
			qcom,remote-pid = <13>;
			transport = "smem";
			mboxes = <&ipcc_mproc IPCC_MPROC_WPSS
				  IPCC_MPROC_SIGNAL_GLINK_QMP>;
			mbox-names = "wpss_smem";
			interrupt-parent = <&ipcc_mproc>;
			interrupts = <IPCC_MPROC_WPSS
					  IPCC_MPROC_SIGNAL_GLINK_QMP
					  IRQ_TYPE_EDGE_RISING>;

			label = "wpss";
			qcom,glink-label = "wpss";

			qcom,wpss_qrtr {
				qcom,glink-channels = "IPCRTR";
				qcom,intents = <0x800  5
						0x2000 3
						0x4400 2>;
			};
		};
	};

	qcom,msm-adsprpc-mem {
		compatible = "qcom,msm-adsprpc-mem-region";
		memory-region = <&adsp_mem_heap>;
		restrict-access;
	};

	clocks {
		xo_board: xo_board {
			compatible = "fixed-clock";
			clock-frequency = <76800000>;
			clock-output-names = "xo_board";
			#clock-cells = <0>;
		};

		sleep_clk: sleep_clk {
			compatible = "fixed-clock";
			clock-frequency = <32000>;
			clock-output-names = "sleep_clk";
			#clock-cells = <0>;
		};

		pcie_0_pipe_clk: pcie_0_pipe_clk {
			compatible = "fixed-clock";
			clock-frequency = <1000>;
			clock-output-names = "pcie_0_pipe_clk";
			#clock-cells = <0>;
		};

		ufs_phy_rx_symbol_0_clk: ufs_phy_rx_symbol_0_clk {
			compatible = "fixed-clock";
			clock-frequency = <1000>;
			clock-output-names = "ufs_phy_rx_symbol_0_clk";
			#clock-cells = <0>;
		};

		ufs_phy_rx_symbol_1_clk: ufs_phy_rx_symbol_1_clk {
			compatible = "fixed-clock";
			clock-frequency = <1000>;
			clock-output-names = "ufs_phy_rx_symbol_1_clk";
			#clock-cells = <0>;
		};

		ufs_phy_tx_symbol_0_clk: ufs_phy_tx_symbol_0_clk {
			compatible = "fixed-clock";
			clock-frequency = <1000>;
			clock-output-names = "ufs_phy_tx_symbol_0_clk";
			#clock-cells = <0>;
		};

		usb3_phy_wrapper_gcc_usb30_pipe_clk: usb3_phy_wrapper_gcc_usb30_pipe_clk {
			compatible = "fixed-clock";
			clock-frequency = <1000>;
			clock-output-names = "usb3_phy_wrapper_gcc_usb30_pipe_clk";
			#clock-cells = <0>;
		};
	};

	cambistmclkcc: clock-controller@1760000 {
		compatible = "qcom,alor-cambistmclkcc", "syscon";
		reg = <0x0 0x1760000 0x0 0x6000>;
		reg-name = "cc_base";
		vdd_mx-supply = <&VDD_MX_LEVEL>;
		clocks = <&rpmhcc RPMH_CXO_CLK>,
			 <&sleep_clk>,
			 <&gcc GCC_CAM_BIST_MCLK_AHB_CLK>;
		clock-names = "bi_tcxo",
			      "sleep_clk",
			      "iface";
		#clock-cells = <1>;
		#reset-cells = <1>;
	};

	camcc_crmc: syscon@954a600 {
		compatible = "syscon";
		reg = <0x0 0x954a600 0x0 0x2000>;
	};

	camcc: clock-controller@956d000 {
		compatible = "qcom,alor-camcc", "syscon";
		reg = <0x0 0x956d000 0x0 0x80000>;
		reg-name = "cc_base";
		vdd_mm-supply = <&VDD_MM_LEVEL>;
		vdd_mx-supply = <&VDD_MX_LEVEL>;
		vdd_mxc-supply = <&VDD_MXC_LEVEL>;
		vdd_mm_mxc_voter-supply = <&VDD_MM_MXC_VOTER_LEVEL>;
		interconnects = <&mmss_noc MASTER_CAMNOC_HF &mc_virt SLAVE_EBI1>;
		interconnect-names = "cam-to-ddr";
		clocks = <&rpmhcc RPMH_CXO_CLK>,
			 <&rpmhcc RPMH_CXO_CLK_A>,
			 <&sleep_clk>,
			 <&gcc GCC_CAMERA_AHB_CLK>;
		clock-names = "bi_tcxo",
			      "bi_tcxo_ao",
			      "sleep_clk",
			      "iface";
		qcom,cam_crm-crmc = <&camcc_crmc>;
		#clock-cells = <1>;
		#reset-cells = <1>;
		#power-domain-cells = <1>;
	};

	dispcc_crm: syscon@9bcc800 {
		compatible = "syscon";
		reg = <0x0 0x9bcc800 0x0 0x2000>;
	};

	dispcc: clock-controller@9ba2000 {
		compatible = "qcom,alor-dispcc", "syscon";
		reg = <0x0 0x9ba2000 0x0 0x20000>;
		reg-name = "cc_base";
		vdd_mm-supply = <&VDD_MM_LEVEL>;
		vdd_mx-supply = <&VDD_MX_LEVEL>;
		clocks = <&rpmhcc RPMH_CXO_CLK>,
			 <&rpmhcc RPMH_CXO_CLK_A>,
			 <&sleep_clk>,
			 <&gcc GCC_DISP_AHB_CLK>;
		clock-names = "bi_tcxo",
			      "bi_tcxo_ao",
			      "sleep_clk",
			      "iface";
		qcom,disp_crm-crmc = <&dispcc_crm>;
		#clock-cells = <1>;
		#power-domain-cells = <1>;
		#reset-cells = <1>;

		dispcc_mx: clock-controller@9ba4000 {
			compatible = "qcom,canoe-dispcc_mx";
			clocks = <&rpmhcc RPMH_CXO_CLK>,
				 <&sleep_clk>;
			clock-names = "bi_tcxo",
				      "sleep_clk";
			#clock-cells = <1>;
		};
	};

	evacc: clock-controller@24f0000 {
		compatible = "qcom,alor-evacc", "syscon";
		reg = <0x0 0x24f0000 0x0 0x10000>;
		reg-name = "cc_base";
		vdd_mm-supply = <&VDD_MM_LEVEL>;
		vdd_mxc-supply = <&VDD_MXC_LEVEL>;
		vdd_mm_mxc_voter-supply = <&VDD_MM_MXC_VOTER_LEVEL>;
		clocks = <&rpmhcc RPMH_CXO_CLK>,
			 <&rpmhcc RPMH_CXO_CLK_A>,
			 <&sleep_clk>,
			 <&gcc GCC_EVA_AHB_CLK>;
		clock-names = "bi_tcxo",
			      "bi_tcxo_ao",
			      "sleep_clk",
			      "iface";
		#clock-cells = <1>;
		#reset-cells = <1>;
		#power-domain-cells = <1>;
	};

	gcc: clock-controller@100000 {
		compatible = "qcom,alor-gcc", "syscon";
		reg = <0x0 0x100000 0x0 0x1f4200>;
		reg-name = "cc_base";
		vdd_cx-supply = <&VDD_CX_LEVEL>;
		vdd_mx-supply = <&VDD_MX_LEVEL>;
		clocks = <&rpmhcc RPMH_CXO_CLK>,
			 <&pcie_0_pipe_clk>,
			 <&sleep_clk>,
			 <&ufs_phy_rx_symbol_0_clk>,
			 <&ufs_phy_rx_symbol_1_clk>,
			 <&ufs_phy_tx_symbol_0_clk>,
			 <&usb3_phy_wrapper_gcc_usb30_pipe_clk>;
		clock-names = "bi_tcxo",
			      "pcie_0_pipe_clk",
			      "sleep_clk",
			      "ufs_phy_rx_symbol_0_clk",
			      "ufs_phy_rx_symbol_1_clk",
			      "ufs_phy_tx_symbol_0_clk",
			      "usb3_phy_wrapper_gcc_usb30_pipe_clk";
		#clock-cells = <1>;
		#reset-cells = <1>;
		#power-domain-cells = <1>;
	};

	gpucc: clock-controller@3d90000 {
		compatible = "qcom,alor-gpucc", "syscon";
		reg = <0x0 0x3d90000 0x0 0x9800>;
		reg-name = "cc_base";
		vdd_cx-supply = <&VDD_CX_LEVEL>;
		vdd_mx-supply = <&VDD_MX_LEVEL>;
		clocks = <&rpmhcc RPMH_CXO_CLK>,
			 <&gcc GCC_GPU_GPLL0_CLK_SRC>,
			 <&gcc GCC_GPU_GPLL0_DIV_CLK_SRC>;
		clock-names = "bi_tcxo",
			      "gpll0_out_main",
			      "gpll0_out_main_div";
		#clock-cells = <1>;
		#reset-cells = <1>;
		#power-domain-cells = <1>;
	};

	gxclkctl: clock-controller@3d68024 {
		compatible = "qcom,canoe-gx_clkctl";
		reg = <0x0 0x3d68024 0x0 0x8>;
		reg-name = "cc_base";
		power-domains = <&gpucc GPU_CC_CX_GDSC>;
		vdd_gfx-supply = <&VDD_GFX_MXC_VOTER_LEVEL>;
		#power-domain-cells = <1>;
	};

	tcsrcc: clock-controller@1fd5044 {
		compatible = "qcom,canoe-tcsrcc", "syscon";
		reg = <0x0 0x1fd5044 0x0 0x1c>;
		reg-name = "cc_base";
		#clock-cells = <1>;
		#reset-cells = <1>;
	};

	videocc: clock-controller@20f0000 {
		compatible = "qcom,alor-videocc", "syscon";
		reg = <0x0 0x20f0000 0x0 0x10000>;
		reg-name = "cc_base";
		vdd_mm-supply = <&VDD_MM_LEVEL>;
		vdd_mxc-supply = <&VDD_MXC_LEVEL>;
		vdd_mm_mxc_voter-supply = <&VDD_MM_MXC_VOTER_LEVEL>;
		clocks = <&rpmhcc RPMH_CXO_CLK>,
			<&rpmhcc RPMH_CXO_CLK_A>,
			<&sleep_clk>,
			<&gcc GCC_VIDEO_AHB_CLK>;
		clock-names = "bi_tcxo",
				"bi_tcxo_ao",
				"sleep_clk",
				"iface";
		#clock-cells = <1>;
		#reset-cells = <1>;
		#power-domain-cells = <1>;
	};

	apsscc: syscon@17c00000 {
		compatible = "syscon";
		reg = <0x0 0x17c00000 0x0 0x8000>;
	};

	gxclkctldebugcc: syscon@3d64000 {
		compatible = "syscon";
		reg = <0x0 0x3d64000 0x0 0x5000>;
	};

	mccc: syscon@310ba000 {
		compatible = "syscon";
		reg = <0x0 0x310ba000 0x0 0x54>;
	};

	debugcc: clock-controller@0 {
		compatible = "qcom,alor-debugcc";
		qcom,apsscc = <&apsscc>;
		qcom,cambistmclkcc = <&cambistmclkcc>;
		qcom,camcc = <&camcc>;
		qcom,dispcc = <&dispcc>;
		qcom,evacc = <&evacc>;
		qcom,gcc = <&gcc>;
		qcom,gpucc = <&gpucc>;
		qcom,gxclkctl = <&gxclkctldebugcc>;
		qcom,videocc = <&videocc>;
		qcom,mccc = <&mccc>;
		clocks = <&rpmhcc RPMH_CXO_CLK>,
			 <&cambistmclkcc 0>,
			 <&camcc 0>,
			 <&dispcc 0>,
			 <&evacc 0>,
			 <&gcc 0>,
			 <&gpucc 0>,
			 <&videocc 0>;
		clock-names = "xo_clk_src",
			      "cambistmclkcc",
			      "camcc",
			      "dispcc",
			      "evacc",
			      "gcc",
			      "gpucc",
			      "videocc";
		#clock-cells = <1>;
	};

	/* GCC GDSCs */
	gcc_usb30_prim_gdsc: qcom,gdsc@139004 {
		compatible = "qcom,gdsc";
		reg = <0x0 0x139004 0x0 0x4>;
		regulator-name = "gcc_usb30_prim_gdsc";
		parent-supply = <&VDD_CX_LEVEL>;
		qcom,retain-regs;
		qcom,support-cfg-gdscr;
		proxy-supply = <&gcc_usb30_prim_gdsc>;
		qcom,proxy-consumer-enable;
	};

	gcc_usb3_phy_gdsc: qcom,gdsc@150018 {
		compatible = "qcom,gdsc";
		reg = <0x0 0x150018 0x0 0x4>;
		regulator-name = "gcc_usb3_phy_gdsc";
		parent-supply = <&VDD_MX_LEVEL>;
		qcom,retain-regs;
		qcom,support-cfg-gdscr;
		proxy-supply = <&gcc_usb3_phy_gdsc>;
		qcom,proxy-consumer-enable;
	};

	apps_rsc: rsc@18900000 {
		label = "apps_rsc";
		compatible = "qcom,rpmh-rsc";
		reg = <0x0 0x18900000 0x0 0x10000>,
		      <0x0 0x18910000 0x0 0x10000>,
		      <0x0 0x18920000 0x0 0x10000>;
		reg-names = "drv-0", "drv-1", "drv-2";
		qcom,drv-count = <3>;
		interrupts = <GIC_SPI 3 IRQ_TYPE_LEVEL_HIGH>,
			     <GIC_SPI 4 IRQ_TYPE_LEVEL_HIGH>,
			     <GIC_SPI 5 IRQ_TYPE_LEVEL_HIGH>;
		power-domains = <&CLUSTER_PD2>;

		apps_rsc_drv2: drv@2 {
			qcom,drv-id = <2>;
			qcom,tcs-offset = <0xd00>;
			qcom,tcs-distance = <0x2a0>;
			channel@0 {
				qcom,tcs-config = <ACTIVE_TCS    3>,
						  <SLEEP_TCS     2>,
						  <WAKE_TCS      2>,
						  <CONTROL_TCS   0>,
						  <FAST_PATH_TCS 1>;
			};

			apps_bcm_voter: bcm_voter {
				compatible = "qcom,bcm-voter";
			};

			rpmhcc: clock-controller {
				compatible = "qcom,alor-rpmh-clk";
				#clock-cells = <1>;
			};

			dcvs_fp: qcom,dcvs-fp {
				compatible = "qcom,dcvs-fp";
				qcom,ddr-bcm-name = "MC4";
				qcom,llcc-bcm-name = "SH5";
			};
		};
	};

	cpucp_sram: cpucp-sram@0x1d838000 {
		#address-cells = <1>;
		#size-cells = <1>;
		compatible = "mmio-sram";
		reg = <0x0 0x1d838000 0x0 0x400>;
		ranges = <0 0x0 0x1d838000 0x400>;

		cpucp_tx: scmi-shmem@0 {
			compatible = "arm,scmi-shmem";
			reg = <0x0 0x200>;
		};

		cpucp_rx: scmi-shmem@1 {
			compatible = "arm,scmi-shmem";
			reg = <0x200 0x200>;
		};
	};

	pdp_sram: pdp-sram@81f08000 {
		#address-cells = <1>;
		#size-cells = <1>;
		compatible = "mmio-sram";
		reg = <0x0 0x81f08000 0x0 0x200>;
		ranges = <0 0x0 0x81f08000 0x200>;

		pdp_rx: scmi-shmem@0 {
			compatible = "arm,scmi-shmem";
			reg = <0x0 0x80>;
		};

		pdp_tx: scmi-shmem@100 {
			compatible = "arm,scmi-shmem";
			reg = <0x100 0x80>;
		};
	};

	cpucp: qcom,cpucp@0x18830000 {
		compatible = "qcom,cpucp-v2";
		reg =	<0x0 0x18830000 0x0 0x300>,
			<0x0 0x17620000 0x0 0x4C08>;
		reg-names = "tx", "rx";
		#mbox-cells = <1>;
		interrupts = <GIC_SPI 28 IRQ_TYPE_LEVEL_HIGH>;
	};

	pdp0: qcom,pdp0@0x19980000 {
		compatible = "qcom,cpucp-v2";
		reg =	<0x0 0x19980000 0x0 0x300>,
			<0x0 0x17610000 0x0 0x4C08>;
		reg-names = "tx", "rx";
		#mbox-cells = <1>;
		interrupts = <GIC_SPI 34 IRQ_TYPE_LEVEL_HIGH>;
		qcom,rx-chans = <0x7>;
	};

	pdp1: qcom,pdp1@0x1a980000 {
		compatible = "qcom,cpucp-v2";
		reg =	<0x0 0x1a980000 0x0 0x300>,
			<0x0 0x17610000 0x0 0x4C08>;
		reg-names = "tx", "rx";
		#mbox-cells = <1>;
		interrupts = <GIC_SPI 34 IRQ_TYPE_LEVEL_HIGH>;
		qcom,rx-chans = <0x8>;
	};

	cpucp_scmi: qcom,cpucp-scmi {
		#address-cells = <1>;
		#size-cells = <0>;
		compatible = "arm,scmi";
		mboxes = <&cpucp 0>, <&cpucp 2>;
		mbox-names = "tx", "rx";
		shmem = <&cpucp_tx>, <&cpucp_rx>;

		cpucp_scmi_clk: protocol@14 {
			reg = <0x14>;
			#clock-cells = <1>;
		};

		cpucp_scmi_qcom: protocol@80 {
			reg = <0x80>;
			#clock-cells = <1>;
		};
	};

	pdp_scmi: qcom,pdp-scmi {
		#address-cells = <1>;
		#size-cells = <0>;
		compatible = "arm,scmi";
		mboxes = <&pdp0 0>, <&pdp0 1>;
		mbox-names = "tx", "rx";
		shmem = <&pdp_tx>, <&pdp_rx>;

		pdp_scmi_perf: protocol@13 {
			reg = <0x13>;
			#clock-cells = <1>;
		};
	};

	cpucp_fast: qcom,cpucp_fast {
		compatible = "qcom,cpucp_fast";
		mboxes = <&cpucp 7>;
		qcom,policy-cpus = < 6 >;
	};

	cpucp_log: qcom,cpucp_log@0x81210000 {
		compatible = "qcom,cpucp-log";
		reg =	<0x0 0x81210000 0x0 0x10000>,
			<0x0 0x81220000 0x0 0x10000>;
		mboxes = <&cpucp 1>;
		qcom,log-type = <0>;
	};

	pdp0_log: qcom,pdp0_log@0x81f4a000 {
		compatible = "qcom,pdp-log";
		reg =	<0x0 0x81f4a000 0x0 0x10000>;
		mboxes = <&pdp0 2>;
		qcom,log-type = <1>;
	};

	pdp1_log: qcom,pdp1_log@0x81f8a000 {
		compatible = "qcom,pdp-log";
		reg =	<0x0 0x81f8a000 0x0 0x10000>;
		mboxes = <&pdp1 3>, <&pdp1 2>;
		qcom,log-type = <2>;
	};

	qcom_mpam: qcom,mpam {
		compatible = "qcom,mpam";
	};

	cpu_mpam: qcom,cpu_mpam {
		compatible = "qcom,cpu-mpam";
		reg = <0x0 0x1d83a000 0x0 0x400>;
		reg-names = "mon-base";

		L2_0 {
			qcom,msc-id = <0>;
			qcom,msc-name = "L2_0";
		};

		L2_1 {
			qcom,msc-id = <1>;
			qcom,msc-name = "L2_1";
		};
	};

	noc_bw_mpam: qcom,noc_bw_mpam {
		compatible = "qcom,platform-mpam";
		reg = <0x0 0x1d83a400 0x0 0x400>;
		reg-names = "mon-base";
		qcom,msc-id = <3>;
		qcom,msc-name = "noc_bw";
		qcom,gears = "low", "medium", "high", "veryhigh";
		qcom,gear-id = <1>, <2>, <3>, <4>;

		cpu_cluster0 {
			qcom,client-id = <0x1>;
			qcom,client-name = "cpu_cluster0";
		};

		cpu_cluster1 {
			qcom,client-id = <0x2>;
			qcom,client-name = "cpu_cluster1";
		};

		gpu {
			qcom,client-id = <0x10>;
			qcom,client-name = "gpu";
		};

		nsp {
			qcom,client-id = <0x100>;
			qcom,client-name = "nsp";
		};
	};

	llcc_pmu: llcc-pmu@0x31095000 {
		compatible = "qcom,llcc-pmu-ver3";
		reg = <0x0 0x31095000 0x0 0x400>;
		reg-names = "lagg-base";
		qcom,idx-tbl =
			< 2 >,
			< 3 >,
			< 4 >,
			< 5 >,
			< 6 >,
			< 7 >,
			< 0 >,
			< 1 >;
	};

	qcom_pmu: qcom,pmu {
		compatible = "qcom,pmu";
		qcom,long-counter;
		qcom,pmu-events-tbl =
			< 0x0008 0xFF 0x02 0x02 >,
			< 0x0011 0xFF 0x01 0x00 >,
			< 0x0017 0xFF 0xFF 0x04 >,
			< 0x1000 0xFF 0xFF 0x08 >;
	};

	ddr_freq_table: ddr-freq-table {
		qcom,freq-tbl =
			<  547000 >,
			< 1353000 >,
			< 1555000 >,
			< 1708000 >,
			< 2092000 >,
			< 2736000 >,
			< 3187000 >,
			< 3686000 >,
			< 4224000 >,
			< 4780000 >;
	};

	llcc_freq_table: llcc-freq-table {
		qcom,freq-tbl =
			<  282000 >,
			<  350000 >,
			<  533000 >,
			<  605600 >,
			<  806000 >,
			<  933000 >,
			< 1066000 >,
			< 1211000 >;
	};

	ddrqos_freq_table: ddrqos-freq-table {
		qcom,freq-tbl =
			< 0 >,
			< 1 >;
	};

	qcom_dcvs: qcom,dcvs {
		compatible = "qcom,dcvs";

		qcom_ddr_dcvs_hw: ddr {
			compatible = "qcom,dcvs-hw";
			qcom,dcvs-hw-type = <0>;
			qcom,bus-width = <4>;
			qcom,freq-tbl = <&ddr_freq_table>;

			ddr_dcvs_sp: sp {
				compatible = "qcom,dcvs-path";
				qcom,dcvs-path-type = <0>;
				interconnects = <&mc_virt MASTER_LLCC
						 &mc_virt SLAVE_EBI1>;
			};

			ddr_dcvs_fp: fp {
				compatible = "qcom,dcvs-path";
				qcom,dcvs-path-type = <1>;
				qcom,fp-voter = <&dcvs_fp>;
			};
		};

		qcom_llcc_dcvs_hw: llcc {
			compatible = "qcom,dcvs-hw";
			qcom,dcvs-hw-type = <1>;
			qcom,bus-width = <16>;
			qcom,freq-tbl = <&llcc_freq_table>;

			llcc_dcvs_sp: sp {
				compatible = "qcom,dcvs-path";
				qcom,dcvs-path-type = <0>;
				interconnects = <&gem_noc MASTER_APPSS_PROC
						 &gem_noc SLAVE_LLCC>;
			};

			llcc_dcvs_fp: fp {
				compatible = "qcom,dcvs-path";
				qcom,dcvs-path-type = <1>;
				qcom,fp-voter = <&dcvs_fp>;
			};
		};

		qcom_ddrqos_dcvs_hw: ddrqos {
			compatible = "qcom,dcvs-hw";
			qcom,dcvs-hw-type = <3>;
			qcom,bus-width = <1>;
			qcom,freq-tbl = <&ddrqos_freq_table>;

			ddrqos_dcvs_sp: sp {
				compatible = "qcom,dcvs-path";
				qcom,dcvs-path-type = <0>;
				interconnects = <&mc_virt MASTER_LLCC
						 &mc_virt SLAVE_EBI1>;
			};
		};
	};

	qcom_memlat: qcom,memlat {
		compatible = "qcom,memlat";

		ddr {
			compatible = "qcom,memlat-grp";
			qcom,target-dev = <&qcom_ddr_dcvs_hw>;
			qcom,sampling-path = <&ddr_dcvs_fp>;
			qcom,miss-ev = <0x1000>;

			gold {
				compatible = "qcom,memlat-mon";
				qcom,cpulist = <&CPU0 &CPU1 &CPU2 &CPU3 &CPU4 &CPU5>;
				qcom,cpufreq-memfreq-tbl =
					<  806400  547000 >,
					< 1036800 1353000 >,
					< 1228800 1555000 >,
					< 1555200 2092000 >,
					< 2611200 3187000 >,
					< 3321600 3686000 >;
				qcom,sampling-enabled;
			};

			prime {
				compatible = "qcom,memlat-mon";
				qcom,cpulist = <&CPU6 &CPU7>;
				qcom,cpufreq-memfreq-tbl =
					<  806400  547000 >,
					<  921600 1353000 >,
					< 1382400 2092000 >,
					< 2112000 3187000 >,
					< 2841600 3686000 >,
					< 3072000 4224000 >,
					< 3430000 4780000 >;
				qcom,sampling-enabled;
			};

			gold-compute {
				compatible = "qcom,memlat-mon";
				qcom,cpulist = <&CPU0 &CPU1 &CPU2 &CPU3 &CPU4 &CPU5 &CPU6 &CPU7>;
				qcom,cpufreq-memfreq-tbl =
					< 1996800  547000 >,
					< 2611200 2092000 >;
				qcom,sampling-enabled;
				qcom,compute-mon;
			};

			prime-latfloor {
				compatible = "qcom,memlat-mon";
				qcom,cpulist = <&CPU6 &CPU7>;
				qcom,cpufreq-memfreq-tbl =
					< 2841600  547000 >,
					< 3072000 4224000 >;
				qcom,sampling-enabled;
			};
		};

		llcc {
			compatible = "qcom,memlat-grp";
			qcom,target-dev = <&qcom_llcc_dcvs_hw>;
			qcom,sampling-path = <&llcc_dcvs_fp>;
			qcom,miss-ev = <0x17>;

			gold {
				compatible = "qcom,memlat-mon";
				qcom,cpulist = <&CPU0 &CPU1 &CPU2 &CPU3 &CPU4 &CPU5>;
				qcom,cpufreq-memfreq-tbl =
					<  806400  282000 >,
					< 1036800  350000 >,
					< 1747200  533000 >,
					< 2611200  806000 >,
					< 3321600  933000 >;
				qcom,sampling-enabled;
			};

			prime {
				compatible = "qcom,memlat-mon";
				qcom,cpulist = <&CPU6 &CPU7>;
				qcom,cpufreq-memfreq-tbl =
					<  806400  282000 >,
					<  921600  350000 >,
					< 1651200  533000 >,
					< 2112000  806000 >,
					< 2841600  933000 >,
					< 3072000 1066000 >,
					< 3430000 1350000 >;
				qcom,sampling-enabled;
			};

			gold-compute {
				compatible = "qcom,memlat-mon";
				qcom,cpulist = <&CPU0 &CPU1 &CPU2 &CPU3 &CPU4 &CPU5 &CPU6 &CPU7>;
				qcom,cpufreq-memfreq-tbl =
					< 1996800  282000 >,
					< 2611200  533000 >;
				qcom,sampling-enabled;
				qcom,compute-mon;
			};
		};

		ddrqos {
			compatible = "qcom,memlat-grp";
			qcom,target-dev = <&qcom_ddrqos_dcvs_hw>;
			qcom,sampling-path = <&ddrqos_dcvs_sp>;
			qcom,miss-ev = <0x1000>;

			ddrqos_gold_lat: gold {
				compatible = "qcom,memlat-mon";
				qcom,cpulist = <&CPU0 &CPU1 &CPU2 &CPU3 &CPU4 &CPU5 &CPU6 &CPU7>;
				qcom,cpufreq-memfreq-tbl =
					< 1900000 0 >,
					< 2800000 1 >;
				qcom,sampling-enabled;
			};

			ddrqos_prime_lat: prime {
				compatible = "qcom,memlat-mon";
				qcom,cpulist = <&CPU6 &CPU7>;
				qcom,cpufreq-memfreq-tbl =
					< 1497000 0 >,
					< 3200000 1 >;
				qcom,sampling-enabled;
			};

			ddrqos_prime_latfloor: prime-latfloor {
				compatible = "qcom,memlat-mon";
				qcom,cpulist = <&CPU6 &CPU7>;
				qcom,cpufreq-memfreq-tbl =
					< 2112000 0 >,
					< 3200000 1 >;
				qcom,sampling-enabled;
			};
		};
	};

	qcom_llcc_ddr_vote: qcom,llcc-ddr-vote {
		qcom,target-dev = <&qcom_ddr_dcvs_hw>;
		qcom,secondary-map =
			<  350000  547000 >,
			<  533000 1555000 >,
			<  605600 2092000 >,
			<  806000 3187000 >,
			<  933000 3686000 >,
			< 1066000 4224000 >,
			< 1211000 4780000 >;
	};

	bwmon_llcc_gold: qcom,bwmon-llcc-gold@310B3300 {
		compatible = "qcom,bwmon4";
		reg = <0x0 0x310B3400 0x0 0x300>, <0x0 0x310B3300 0x0 0x200>;
		reg-names = "base", "global_base";
		interrupts = <GIC_SPI 581 IRQ_TYPE_LEVEL_HIGH>;
		qcom,mport = <0>;
		qcom,hw-timer-hz = <19200000>;
		qcom,count-unit = <0x10000>;
		qcom,target-dev = <&qcom_llcc_dcvs_hw>;
		qcom,second-vote = <&qcom_llcc_ddr_vote>;
	};

	bwmon_llcc_prime: qcom,bwmon-llcc-prime@310B7300 {
		compatible = "qcom,bwmon4";
		reg = <0x0 0x310B7400 0x0 0x300>, <0x0 0x310B7300 0x0 0x200>;
		reg-names = "base", "global_base";
		interrupts = <GIC_SPI 581 IRQ_TYPE_LEVEL_HIGH>;
		qcom,mport = <0>;
		qcom,hw-timer-hz = <19200000>;
		qcom,count-unit = <0x10000>;
		qcom,target-dev = <&qcom_llcc_dcvs_hw>;
		qcom,second-vote = <&qcom_llcc_ddr_vote>;
	};

	bwmon_ddr: qcom,bwmon-ddr@31091000 {
		compatible = "qcom,bwmon5";
		reg = <0x0 0x31091000 0x0 0x1000>;
		reg-names = "base";
		interrupts = <GIC_SPI 81 IRQ_TYPE_LEVEL_HIGH>;
		qcom,hw-timer-hz = <19200000>;
		qcom,count-unit = <0x10000>;
		qcom,target-dev = <&qcom_ddr_dcvs_hw>;
	};

	cam_rsc: rsc@9545000 {
		label = "cam_rsc";
		compatible = "qcom,rpmh-rsc";
		reg = <0x0 0x9545000 0x0 0x1000>,
		      <0x0 0x9546000 0x0 0x1000>,
		      <0x0 0x9547000 0x0 0x1000>;
		reg-names = "drv-0", "drv-1", "drv-2";
		qcom,drv-count = <3>;
		qcom,hw-channel;
		interrupts = <GIC_SPI 368 IRQ_TYPE_LEVEL_HIGH>,
			     <GIC_SPI 369 IRQ_TYPE_LEVEL_HIGH>,
			     <GIC_SPI 370 IRQ_TYPE_LEVEL_HIGH>;

		cam_rsc_drv0: drv@0 {
			qcom,drv-id = <0>;
			qcom,tcs-offset = <0x520>;
			qcom,tcs-distance = <0x150>;
			channel@0 {
				qcom,tcs-config = <ACTIVE_TCS    0>,
						  <WAKE_TCS      1>,
						  <SLEEP_TCS     1>,
						  <CONTROL_TCS   0>,
						  <FAST_PATH_TCS 0>;
			};

			channel@1 {
				qcom,tcs-config = <ACTIVE_TCS    0>,
						  <WAKE_TCS      1>,
						  <SLEEP_TCS     1>,
						  <CONTROL_TCS   0>,
						  <FAST_PATH_TCS 0>;
			};

			cam_bcm_voter0: bcm_voter {
				compatible = "qcom,bcm-voter";
				qcom,no-amc;
			};
		};

		cam_rsc_drv1: drv@1 {
			qcom,drv-id = <1>;
			qcom,tcs-offset = <0x520>;
			qcom,tcs-distance = <0x150>;
			channel@0 {
				qcom,tcs-config = <ACTIVE_TCS    0>,
						  <WAKE_TCS      1>,
						  <SLEEP_TCS     1>,
						  <CONTROL_TCS   0>,
						  <FAST_PATH_TCS 0>;
			};

			channel@1 {
				qcom,tcs-config = <ACTIVE_TCS    0>,
						  <WAKE_TCS      1>,
						  <SLEEP_TCS     1>,
						  <CONTROL_TCS   0>,
						  <FAST_PATH_TCS 0>;
			};

			cam_bcm_voter1: bcm_voter {
				compatible = "qcom,bcm-voter";
				qcom,no-amc;
			};
		};

		cam_rsc_drv2: drv@2 {
			qcom,drv-id = <2>;
			qcom,tcs-offset = <0x520>;
			qcom,tcs-distance = <0x150>;
			channel@0 {
				qcom,tcs-config = <ACTIVE_TCS    0>,
						  <WAKE_TCS      1>,
						  <SLEEP_TCS     1>,
						  <CONTROL_TCS   0>,
						  <FAST_PATH_TCS 0>;
			};

			channel@1 {
				qcom,tcs-config = <ACTIVE_TCS    0>,
						  <WAKE_TCS      1>,
						  <SLEEP_TCS     1>,
						  <CONTROL_TCS   0>,
						  <FAST_PATH_TCS 0>;
			};

			cam_bcm_voter2: bcm_voter {
				compatible = "qcom,bcm-voter";
				qcom,no-amc;
			};
		};
	};

	pdc: interrupt-controller@b220000 {
		compatible = "qcom,alor-pdc", "qcom,pdc";
		reg = <0x0 0xb220000 0x0 0x10000>, <0x0 0x179600f0 0x0 0xf8>;
		qcom,pdc-ranges = <0 745 38>, <40 785 11>, <51 527 4>,
				  <58 534 2>, <61 537 20>, <84 559 14>,
				  <98 609 32>, <130 717 12>, <142 251 5>,
				  <147 796 16>, <163 783 2>, <165 531 2>,
				  <167 536 1>, <168 557 2>, <170 415 1>,
				  <171 438 1>, <172 579 1>, <173 703 1>,
				  <174 708 1>, <175 714 1>, <176 68 1>,
				  <177 86 1>, <178 96 1>, <179 249 1>,
				  <180 504 9>;
		#interrupt-cells = <2>;
		interrupt-parent = <&intc>;
		interrupt-controller;
	};

	qcom,rmtfs_sharedmem@0 {
		compatible = "qcom,sharedmem-uio";
		reg = <0x0 0x0 0x0 0x400000>;
		reg-names = "rmtfs";
		qcom,client-id = <0x00000001>;
	};

	sdhc2_opp_table: sdhc2-opp-table {
		compatible = "operating-points-v2";

		opp-100000000 {
			opp-hz = /bits/ 64 <100000000>;
			opp-peak-kBps = <160000 100000>;
			opp-avg-kBps = <50000 0>;
		};

		opp-202000000 {
			opp-hz = /bits/ 64 <202000000>;
			opp-peak-kBps = <200000 120000>;
			opp-avg-kBps = <104000 0>;
		};
	};


	sdhc_2_dma_resv: sdhc_2_dma_resv_region {
		/*
		 * Restrict IOVA mappings for SDHC2 buffers to the 256 MB region
		 * from 0x40000000 - 0x4fffffff.
		 */
		iommu-addresses = <&sdhc_2 0x0 0x0 0x0 0x40000000>,
				  <&sdhc_2 0x0 0x50000000 0xffffffff 0xb0000000>;
	};

	sdhc_2: sdhci@8804000 {
		compatible = "qcom,sdhci-msm-v5";
		reg = <0x0 0x8804000 0x0 0x1000>;
		reg-names = "hc";

		interrupts = <GIC_SPI 207 IRQ_TYPE_LEVEL_HIGH>,
				<GIC_SPI 223 IRQ_TYPE_LEVEL_HIGH>;
		interrupt-names = "hc_irq", "pwr_irq";

		bus-width = <4>;
		no-sdio;
		no-mmc;
		qcom,restore-after-cx-collapse;
		qcom,uses_level_shifter;

		clocks = <&gcc GCC_SDCC2_AHB_CLK>,
			 <&gcc GCC_SDCC2_APPS_CLK>;
		clock-names = "iface", "core";

		/*
		 * DLL HSR settings. Refer go/hsr - <Target> DLL settings.
		 * Note that the DLL_CONFIG_2 value is not passed from the
		 * device tree, but it is calculated in the driver.
		 */
		qcom,dll-hsr-list = <0x0007442C 0x0 0x10
					0x294106C0 0x80040868>;

		iommus = <&apps_smmu 0x140 0x0>;
		qcom,iommu-dma = "fastmap";
		dma-coherent;
		memory-region = <&sdhc_2_dma_resv>;
		qcom,iommu-geometry = <0x0 0x40000000 0x0 0x10000000>;

		interconnects = <&aggre1_noc MASTER_SDCC_2 &mc_virt SLAVE_EBI1>,
			      <&gem_noc MASTER_APPSS_PROC &config_noc SLAVE_SDCC_2>;
		interconnect-names = "sdhc-ddr", "cpu-sdhc";
		operating-points-v2 = <&sdhc2_opp_table>;

		status = "disabled";

		qos0 {
			mask = <0xf0>;
			vote = <44>;
		};

		qos1 {
			mask = <0x0f>;
			vote = <44>;
		};
	};

	ufsphy_mem: ufsphy_mem@1d80000 {
		reg = <0x0 0x1d80000 0x0 0x2000>;
		reg-names = "phy_mem";
		#phy-cells = <0>;

		power-domains = <&gcc GCC_UFS_MEM_PHY_GDSC>;
		lanes-per-direction = <2>;
		clock-names = "ref_clk_src",
			"ref_aux_clk", "qref_clk",
			"rx_sym0_mux_clk", "rx_sym1_mux_clk", "tx_sym0_mux_clk",
			"rx_sym0_phy_clk", "rx_sym1_phy_clk", "tx_sym0_phy_clk";
		clocks = <&rpmhcc RPMH_CXO_CLK>,
			<&gcc GCC_UFS_PHY_PHY_AUX_CLK>,
			<&tcsrcc TCSR_UFS_CLKREF_EN>,
			<&gcc GCC_UFS_PHY_RX_SYMBOL_0_CLK_SRC>,
			<&gcc GCC_UFS_PHY_RX_SYMBOL_1_CLK_SRC>,
			<&gcc GCC_UFS_PHY_TX_SYMBOL_0_CLK_SRC>,
			<&ufs_phy_rx_symbol_0_clk>,
			<&ufs_phy_rx_symbol_1_clk>,
			<&ufs_phy_tx_symbol_0_clk>;
		resets = <&ufshc_mem 0>;
		status = "disabled";
	};

	ice_cfg: shared_ice {
		alg1 {
			alg-name = "alg1";
			rx-alloc-percent = <60>;
			status = "disabled";
		};

		alg2 {
			alg-name = "alg2";
			status = "disabled";

		};

		alg3 {
			alg-name = "alg3";
			num-core = <28 28 15 13>;
			status = "ok";
		};
	};

	qcom_cedev: qcedev@1de0000 {
		compatible = "qcom,qcedev";
		reg = <0x0 0x1de0000 0x0 0x20000>,
			<0x0 0x1dc4000 0x0 0x22000>;
		reg-names = "crypto-base","crypto-bam-base";
		interrupts = <GIC_SPI 272 IRQ_TYPE_LEVEL_HIGH>,
			<GIC_SPI 274 IRQ_TYPE_EDGE_RISING>;
		interrupt-names = "bam-irq", "core-irq";
		qcom,bam-pipe-pair = <2>;
		qcom,offload-ops-support;
		qcom,use-key-index;
		qcom,bam-pipe-offload-cpb-hlos = <1>;
		qcom,bam-pipe-offload-hlos-cpb = <3>;
		qcom,bam-pipe-offload-hlos-cpb-1 = <8>;
		qcom,bam-pipe-offload-hlos-hlos = <4>;
		qcom,bam-pipe-offload-hlos-hlos-1 = <9>;
		qcom,ce-hw-instance = <0>;
		qcom,ce-device = <0>;
		qcom,ce-hw-shared;
		qcom,bam-ee = <0>;
		qcom,smmu-s1-enable;
		qcom,no-clock-support;
		interconnect-names = "data_path";
		interconnects = <&aggre2_noc MASTER_CRYPTO &mc_virt SLAVE_EBI1>;
		iommus = <&apps_smmu 0x00C0 0x0>,
			<&apps_smmu 0x00C1 0x0>;
		qcom,iommu-dma = "atomic";
		dma-coherent;

		qcom_cedev_ns_cb {
			compatible = "qcom,qcedev,context-bank";
			label = "ns_context";
			iommus = <&apps_smmu 0x00C1 0x0>;
			dma-coherent;
		};

		qcom_cedev_s_cb {
			compatible = "qcom,qcedev,context-bank";
			label = "secure_context";
			iommus = <&apps_smmu 0x00C3 0x0>;
			qcom,iommu-vmid = <0x9>;
			qcom,secure-context-bank;
			dma-noncoherent;
		};
	};

	rng: rng@10c3000 {
		compatible = "qcom,trng";
		reg = <0x0 0x10c3000 0x0 0x1000>;
	};

	ufshc_dma_resv: ufshc_dma_resv_region {
		/*
		 * Restrict IOVA mappings for UFSHC buffers to the 3 GB region
		 * from 0x1000 - 0xffffffff.
		 */
		iommu-addresses = <&ufshc_mem 0x0 0x0 0x0 0x1000>;
	};

	ufshc_opp_table: ufshc-opp-table {
		compatible = "operating-points-v2";
		// LOW_SVS
		opp-100000000 {
			opp-hz = /bits/ 64 <100000000>,
				 /bits/ 64 <0>,
				 /bits/ 64 <0>,
				 /bits/ 64 <100000000>,
				 /bits/ 64 <100000000>,
				 /bits/ 64 <0>,
				 /bits/ 64 <0>,
				 /bits/ 64 <0>,
				 /bits/ 64 <0>;
		};

		// NOM/TURBO
		opp-403000000 {
			opp-hz = /bits/ 64 <403000000>,
				 /bits/ 64 <0>,
				 /bits/ 64 <0>,
				 /bits/ 64 <403000000>,
				 /bits/ 64 <403000000>,
				 /bits/ 64 <0>,
				 /bits/ 64 <0>,
				 /bits/ 64 <0>,
				 /bits/ 64 <0>;
		};
	};

	ufshc_mem: ufshc@1d84000 {
		compatible = "qcom,ufshc";
		reg = <0x0 0x1d84000 0x0 0x3000>,
		      <0x0 0x1d88000 0x0 0x18000>,
		      <0x0 0x1da5000 0x0 0x2000>,
		      <0x0 0x1da4000 0x0 0x10>;
		reg-names = "ufs_mem", "ice", "mcq_sqd", "mcq_vs";

		interrupts = <GIC_SPI 265 IRQ_TYPE_LEVEL_HIGH>;
		phys = <&ufsphy_mem>;
		phy-names = "ufsphy";
		#reset-cells = <1>;

		qcom,ice-use-hwkm;
		power-domains = <&gcc GCC_UFS_PHY_GDSC>;
		lanes-per-direction = <2>;

		qcom,prime-mask = <0xc0>;
		qcom,silver-mask = <0x3f>;
		qcom,cluster-mask = <0x3f 0xc0>;
		/* affine cpu for each CQ starting from CQ:0 to CQ:max_cqs */
		qcom,esi-affinity-mask = <4 5 3 4 5 3 7 7>;

		clock-names =
			"core_clk",
			"bus_aggr_clk",
			"iface_clk",
			"core_clk_unipro",
			"core_clk_ice",
			"ref_clk",
			"tx_lane0_sync_clk",
			"rx_lane0_sync_clk",
			"rx_lane1_sync_clk";
		clocks =
			<&gcc GCC_UFS_PHY_AXI_CLK>,
			<&gcc GCC_AGGRE_UFS_PHY_AXI_CLK>,
			<&gcc GCC_UFS_PHY_AHB_CLK>,
			<&gcc GCC_UFS_PHY_UNIPRO_CORE_CLK>,
			<&gcc GCC_UFS_PHY_ICE_CORE_CLK>,
			<&rpmhcc RPMH_LN_BB_CLK3>,
			<&gcc GCC_UFS_PHY_TX_SYMBOL_0_CLK>,
			<&gcc GCC_UFS_PHY_RX_SYMBOL_0_CLK>,
			<&gcc GCC_UFS_PHY_RX_SYMBOL_1_CLK>;

		operating-points-v2 = <&ufshc_opp_table>;
		interconnects = <&aggre1_noc MASTER_UFS_MEM &mc_virt SLAVE_EBI1>,
				<&gem_noc MASTER_APPSS_PROC &config_noc SLAVE_UFS_MEM_CFG>;
		interconnect-names = "ufs-ddr", "cpu-ufs";

		/* set the dependency that smmu being probed before ufs */
		depends-on-supply = <&apps_smmu>;
		iommus = <&apps_smmu 0x60 0x0>;
		qcom,iommu-dma = "fastmap";
		qcom,iommu-msi-size = <0x1000>;
		msi-parent = <&gic_its 0x60>;
		memory-region = <&ufshc_dma_resv>;
		shared-ice-cfg = <&ice_cfg>;
		dma-coherent;

		reset-gpios = <&tlmm 205 GPIO_ACTIVE_LOW>;
		resets = <&gcc GCC_UFS_PHY_BCR>;
		reset-names = "rst";

		qcom,bypass-pbl-rst-wa;
		qcom,max-cpus = <8>;
		status = "disabled";

		qos0 {
			vote = <44>;
			mask = <0x3f>;
			perf;
		};

		qos1 {
			vote = <44>;
			mask = <0xc0>;
		};
	};

	cpuss-sleep-stats@18870000 {
		compatible = "qcom,cpuss-sleep-stats-v6";
		reg = <0x0 0x18870000 0x0 0x4000>;
		reg-names = "base";
		num-clusters = <2>;
	};

	sys-pm-vx@c320000 {
		compatible = "qcom,sys-pm-violators", "qcom,sys-pm-alor";
		reg = <0x0 0xc320000 0x0 0x400>;
		qcom,qmp = <&aoss_qmp>;
	};

	sram@c3f0000 {
		compatible = "qcom,rpmh-stats-v4";
		reg = <0x0 0xc3f0000 0x0 0x400>;
		qcom,qmp = <&aoss_qmp>;
		ss-name = "modem", "adsp", "adsp_island",
			  "cdsp", "apss", "wpss";
	};

	cluster-device0 {
		compatible = "qcom,lpm-cluster-dev";
		power-domains = <&CLUSTER_PD0>;
		qcom,pred-prem-cnt = <2>;
		qcom,sample-invalid-time = <40000000>;
	};

	cluster-device1 {
		compatible = "qcom,lpm-cluster-dev";
		power-domains = <&CLUSTER_PD1>;
		qcom,pred-prem-cnt = <2>;
		qcom,sample-invalid-time = <40000000>;
		qcom,use-cluster-bias-timer;
	};

	cluster-device2 {
		compatible = "qcom,lpm-cluster-dev";
		power-domains = <&CLUSTER_PD2>;
		qcom,pred-prem-cnt = <2>;
		qcom,sample-invalid-time = <40000000>;
	};

	trust_ui_vm_vblk0_ring: trust_ui_vm_vblk0_ring {
		size = <0x4000>;
		gunyah-label = <0x11>;
	};

	trust_ui_vm_vblk1_ring: trust_ui_vm_vblk1_ring {
		size = <0x4000>;
		gunyah-label = <0x10>;
	};

	trust_ui_vm_swiotlb: trust_ui_vm_swiotlb {
		size = <0x400000>;
		gunyah-label = <0x12>;
	};

	trust_ui_vm: qcom,trust_ui_vm {
		vm_name = "trustedvm";
		shared-buffers-size = <0x408000>;
		shared-buffers = <&trust_ui_vm_vblk0_ring &trust_ui_vm_vblk1_ring &trust_ui_vm_swiotlb>;
	};

	trust_ui_vm_virt_be0: trust_ui_vm_virt_be0@11 {
		qcom,vm = <&trust_ui_vm>;
		qcom,label = <0x11>;
	};

	trust_ui_vm_virt_be1: trust_ui_vm_virt_be1@10 {
		qcom,vm = <&trust_ui_vm>;
		qcom,label = <0x10>;
	};

	gunyah-cma-mem {
		compatible = "gunyah-cma-vm-mem";
		memory-region = <&trust_ui_vm_mem &oem_vm_mem>;
		memory-region-names = "trustedvm_cma" , "oemvm_cma";
	};

	qcom,lcp-dare-dare-pool {
		compatible = "qcom,mem-prot-pool";
		memory-region = <&lcp_dare_pool>;
		qcom,lcp-dare;
	};

	gh_secure_vm_loader0: gh-secure-vm-loader@0 {
		compatible = "qcom,gh-secure-vm-loader";
		qcom,pas-id = <28>;
		qcom,vmid = <45>;
		qcom,firmware-name = "trustedvm";
		qcom,keep-running;
		memory-region = <&trust_ui_vm_mem &vm_comm_mem>;
		virtio-backends = <&trust_ui_vm_virt_be0 &trust_ui_vm_virt_be1>;
	};

	oem_vm_vblk0_ring: oem_vm_vblk0_ring {
		size = <0x4000>;
		gunyah-label = <0x16>; /* persist */
	};

	oem_vm_vblk1_ring: oem_vm_vblk1_ring {
		size = <0x4000>;
		gunyah-label = <0x13>; /* system */
	};

	oem_vm_swiotlb: oem_vm_swiotlb {
		size = <0x100000>;
		gunyah-label = <0x14>;
	};

	oem_vm: qcom,oem_vm {
		vm_name = "oemvm";
		shared-buffers-size = <0x108000>;
		shared-buffers = <&oem_vm_vblk0_ring &oem_vm_vblk1_ring &oem_vm_swiotlb>;
	};

	oem_vm_virt_be0: oem_vm_virt_be0@16 {
		qcom,vm = <&oem_vm>;
		qcom,label = <0x16>; /* persist */
	};

	oem_vm_virt_be1: oem_vm_virt_be1@13 {
		qcom,vm = <&oem_vm>;
		qcom,label = <0x13>; /* system */
	};

	gh_secure_vm_loader1: gh-secure-vm-loader@1 {
		compatible = "qcom,gh-secure-vm-loader";
		qcom,pas-id = <34>;
		qcom,vmid = <49>;
		qcom,firmware-name = "oemvm";
		qcom,keep-running;
		memory-region = <&oem_vm_mem &vm_comm_mem>;
		virtio-backends = <&oem_vm_virt_be0 &oem_vm_virt_be1>;
	};

	qcom,test-dbl-tuivm {
		compatible = "qcom,gh-dbl";
		qcom,label = <0x104>;
	};

	qcom,test-dbl-oemvm {
		compatible = "qcom,gh-dbl";
		qcom,label = <0x105>;
	};

	qcom,test-msgq-tuivm {
		compatible = "qcom,gh-msgq-test";
		gunyah-label = <0x104>;
		qcom,primary;
	};

	qcom,test-msgq-oemvm {
		compatible = "qcom,gh-msgq-test";
		gunyah-label = <0x105>;
		qcom,primary;
	};

	qcom,qrtr-gunyah-tuivm {
		compatible = "qcom,qrtr-gunyah";
		qcom,master;
		gunyah-label = <0x103>;
		peer-name = <2>;
	};

	qcom,gh-qtimer@1781b000 {
		compatible = "qcom,gh-qtmr";
		reg = <0x0 0x1781b000 0x0 0x1000>;
		reg-names = "qtmr-base";
		interrupts = <GIC_SPI 13 IRQ_TYPE_LEVEL_HIGH>;
		interrupt-names = "qcom,qtmr-intr";
		qcom,primary;
	};

	qcom,gunyah-panic-notifier {
		compatible = "qcom,gh-panic-notifier";
		qcom,primary-vm;
		gunyah-label = <0x109>;
		peer-name = <2>;
		memory-region = <&vm_comm_mem>;
		shared-buffer-size = <0x1000>;
	};

	dmesg-dump {
		compatible = "qcom,dmesg-dump";
		qcom,primary-vm;
		gunyah-label = <0x107>;
		peer-name = <2>;
		memory-region = <&vm_comm_mem>;
		shared-buffer-size = <0x1000>;
	};

	tlmm-vm-mem-access {
		compatible = "qcom,tlmm-vm-mem-access";
		qcom,master;

		tuivm {
			qcom,label = <0x08>;
			qcom,vmid = <45>;
			tlmm-vm-gpio-list = <&tlmm 12 0 &tlmm 48 0 &tlmm 49 0 &tlmm 50 0 &tlmm 51 0
					&tlmm 68 0 &tlmm 69 0 &tlmm 70 0 &tlmm 71 0 &tlmm 87 0
					&tlmm 100 0 &tlmm 128 0 &tlmm 146 0 &tlmm 86 0 &tlmm 88 0
					&tlmm 161 0 &tlmm 55 0>;
		};
	};

	tlmm-vm-test {
		compatible = "qcom,tlmm-vm-test";
		qcom,master;
		tlmm-vm-gpio-list = <&tlmm 12 0>;
	};

	adsp_sleepmon: adsp-sleepmon {
		compatible = "qcom,adsp-sleepmon";
		qcom,rproc-handle = <&adsp_pas>;
	};

	qcom,qrtr-mhi-cnss {
		compatible = "qcom,qrtr-mhi";
		qcom,dev-id = <0x1103>;
		qcom,net-id = <0>;
		qcom,low-latency;
	};

	qcom,qrtr-mhi-cnss {
		compatible = "qcom,qrtr-mhi";
		qcom,dev-id = <0x1107>;
		qcom,net-id = <1>;
		qcom,low-latency;
	};

	qcom,qrtr-mhi-cnss {
		compatible = "qcom,qrtr-mhi";
		qcom,dev-id = <0x110E>;
		qcom,net-id = <0>;
		qcom,low-latency;
	};

	modem_pas: remoteproc-mss@04080000 {
		compatible = "qcom,alor-modem-pas";
		reg = <0x0 0x4080000 0x0 0x10000>;
		status = "ok";

		clocks = <&rpmhcc RPMH_CXO_CLK>;
		clock-names = "xo";

		cx-supply = <&VDD_CX_LEVEL>;
		cx-uV-uA = <RPMH_REGULATOR_LEVEL_TURBO 100000>;
		mx-supply = <&VDD_MODEM_LEVEL>;
		mx-uV-uA = <RPMH_REGULATOR_LEVEL_NOM_L1 100000>;
		reg-names = "cx", "mx";

		qcom,qmp = <&aoss_qmp>;

		interconnects = <&mc_virt MASTER_LLCC &mc_virt SLAVE_EBI1>,
				<&aggre2_noc MASTER_CRYPTO &mc_virt SLAVE_EBI1>;
		interconnect-names = "rproc_ddr", "crypto_ddr";

		firmware-name = "modem.mdt", "modem_dtb.mdt";
		memory-region = <&mpss_mem &q6_mpss_dtb_mem &system_cma &dsm_partition_1_mem &dsm_partition_2_mem>;

		/* Inputs from mss */
		interrupts-extended = <&intc GIC_SPI 264 IRQ_TYPE_EDGE_RISING>,
					<&modem_smp2p_in 0 0>,
					<&modem_smp2p_in 2 0>,
					<&modem_smp2p_in 1 0>,
					<&modem_smp2p_in 3 0>,
					<&modem_smp2p_in 7 0>;

		interrupt-names = "wdog",
				"fatal",
				"handover",
				"ready",
				"stop-ack",
				"shutdown-ack";

		/* Outputs to mss */
		qcom,smem-states = <&modem_smp2p_out 0>;
		qcom,smem-state-names = "stop";

		glink-edge {
			qcom,remote-pid = <1>;
			transport = "smem";
			mboxes = <&ipcc_mproc IPCC_MPROC_MPSS
				  IPCC_MPROC_SIGNAL_GLINK_QMP>;
			mbox-names = "mpss_smem";
			interrupt-parent = <&ipcc_mproc>;
			interrupts = <IPCC_MPROC_MPSS
				      IPCC_MPROC_SIGNAL_GLINK_QMP
				      IRQ_TYPE_EDGE_RISING>;

			label = "modem";
			qcom,glink-label = "mpss";

			qcom,modem_qrtr {
				qcom,glink-channels = "IPCRTR";
				qcom,low-latency;
				qcom,intents = <0x800  5
						0x2000 3
						0x4400 2>;
			};

			qcom,modem_ds {
				qcom,glink-channels = "DS";
				qcom,intents = <0x4000 0x2>;
			};
		};
	};

	adsp_pas: remoteproc-adsp@06800000 {
		compatible = "qcom,alor-adsp-pas";
		reg = <0x0 0x06800000 0x0 0x10000>;
		status = "ok";

		cx-supply = <&VDD_LPI_CX_LEVEL>;
		cx-uV-uA = <RPMH_REGULATOR_LEVEL_NOM 0>;
		mx-supply = <&VDD_LPI_MX_LEVEL>;
		mx-uV-uA = <RPMH_REGULATOR_LEVEL_NOM 0>;
		reg-names = "cx", "mx";

		clocks = <&rpmhcc RPMH_CXO_CLK>;
		clock-names = "xo";

		qcom,qmp = <&aoss_qmp>;

		interconnects = <&lpass_lpicx_noc MASTER_LPASS_PROC &mc_virt SLAVE_EBI1>,
				<&aggre2_noc MASTER_CRYPTO &mc_virt SLAVE_EBI1>;
		interconnect-names = "rproc_ddr", "crypto_ddr";

		firmware-name = "adsp.mdt", "adsp_dtb.mdt";
		memory-region = <&adspslpi_mem &q6_adsp_dtb_mem>;

		/* Inputs from ssc */
		interrupts-extended = <&pdc 6 IRQ_TYPE_EDGE_RISING>,
					<&adsp_smp2p_in 0 0>,
					<&adsp_smp2p_in 2 0>,
					<&adsp_smp2p_in 1 0>,
					<&adsp_smp2p_in 3 0>,
					<&adsp_smp2p_in 7 0>;

		interrupt-names = "wdog",
				"fatal",
				"handover",
				"ready",
				"stop-ack",
				"shutdown-ack";

		/* Outputs to turing */
		qcom,smem-states = <&adsp_smp2p_out 0>;
		qcom,smem-state-names = "stop";

		remoteproc_adsp_glink: glink-edge {
			qcom,remote-pid = <2>;
			transport = "smem";
			mboxes = <&ipcc_mproc IPCC_MPROC_LPASS
				  IPCC_MPROC_SIGNAL_GLINK_QMP>;
			mbox-names = "adsp_smem";
			interrupt-parent = <&ipcc_mproc>;
			interrupts = <IPCC_MPROC_LPASS
				      IPCC_MPROC_SIGNAL_GLINK_QMP
				      IRQ_TYPE_EDGE_RISING>;

			label = "adsp";
			qcom,glink-label = "lpass";

			qcom,adsp_qrtr {
				qcom,glink-channels = "IPCRTR";
				qcom,net-id = <2>;
				qcom,intents = <0x800  5
						0x2000 3
						0x4400 2>;

				qcom,no-wake-svc = <0x190>;
			};

			qcom,msm_adspsleepmon_rpmsg {
				compatible = "qcom,msm-adspsleepmon-rpmsg";
				qcom,glink-channels = "sleepmonglink-apps-adsp";
				qcom,intents = <0x1000 8>;
			};
		};
	};

	cdsp_pas: remoteproc-cdsp@26300000 {
		compatible = "qcom,alor-cdsp-pas";
		reg = <0x0 0x26300000 0x0 0x10000>;
		status = "ok";

		cx-supply = <&VDD_CX_LEVEL>;
		cx-uV-uA = <RPMH_REGULATOR_LEVEL_TURBO 100000>;
		mx-supply = <&VDD_MXC_LEVEL>;
		mx-uV-uA = <RPMH_REGULATOR_LEVEL_TURBO 100000>;
		nsp-supply = <&VDD_NSP1_LEVEL>;
		nsp-uV-uA = <RPMH_REGULATOR_LEVEL_TURBO 100000>;
		reg-names = "cx","mx","nsp";

		firmware-name = "cdsp.mdt", "cdsp_dtb.mdt";
		memory-region = <&cdsp_mem &q6_cdsp_dtb_mem>;

		clocks = <&rpmhcc RPMH_CXO_CLK>;
		clock-names = "xo";

		qcom,qmp = <&aoss_qmp>;

		interconnects = <&nsp_noc MASTER_CDSP_PROC &mc_virt SLAVE_EBI1>,
				<&aggre2_noc MASTER_CRYPTO &mc_virt SLAVE_EBI1>;
		interconnect-names = "rproc_ddr", "crypto_ddr";

		/* Inputs from turing */
		interrupts-extended = <&intc GIC_SPI 578 IRQ_TYPE_EDGE_RISING>,
					<&cdsp_smp2p_in 0 0>,
					<&cdsp_smp2p_in 2 0>,
					<&cdsp_smp2p_in 1 0>,
					<&cdsp_smp2p_in 3 0>,
					<&cdsp_smp2p_in 7 0>;

		interrupt-names = "wdog",
				"fatal",
				"handover",
				"ready",
				"stop-ack",
				"shutdown-ack";

		/* Outputs to turing */
		qcom,smem-states = <&cdsp_smp2p_out 0>;
		qcom,smem-state-names = "stop";

		remoteproc_cdsp_glink: glink-edge {
			qcom,remote-pid = <5>;
			transport = "smem";
			mboxes = <&ipcc_mproc IPCC_MPROC_CDSP
				  IPCC_MPROC_SIGNAL_GLINK_QMP>;
			mbox-names = "cdsp_smem";
			interrupt-parent = <&ipcc_mproc>;
			interrupts = <IPCC_MPROC_CDSP
				      IPCC_MPROC_SIGNAL_GLINK_QMP
				      IRQ_TYPE_EDGE_RISING>;

			label = "cdsp";
			qcom,glink-label = "cdsp";

			qcom,cdsp_qrtr {
				qcom,glink-channels = "IPCRTR";
				qcom,intents = <0x800  5
						0x2000 3
						0x4400 2>;
			};

			qcom,msm_cdsprm_rpmsg {
				compatible = "qcom,msm-cdsprm-rpmsg";
				qcom,glink-channels = "cdsprmglink-apps-dsp";
				qcom,intents = <0x20 12
						0xF00 12>;

				msm_cdsp_rm: qcom,msm_cdsp_rm {
					compatible = "qcom,msm-cdsp-rm";
					qcom,qos-cores = <0 1>;
					qcom,qos-latency-us = <70>;
					qcom,qos-maxhold-ms = <20>;
				};
			};
		};
	};

	soccp_pas: remoteproc-soccp@a3380000 {
		compatible = "qcom,alor-soccp-pas";
		reg = <0x0 0xa3380000 0x0 0x10000>;
		status = "ok";

		cx-supply = <&VDD_CX_LEVEL>;
		cx-uV-uA = <RPMH_REGULATOR_LEVEL_LOW_SVS 0>;
		mx-supply = <&VDD_MX_LEVEL>;
		mx-uV-uA = <RPMH_REGULATOR_LEVEL_LOW_SVS 0>;
		reg-names = "cx", "mx";

		clocks = <&rpmhcc RPMH_CXO_CLK>;
		clock-names = "xo";

		firmware-name = "soccp.mbn", "soccp_dtb.mbn";

		memory-region = <&soccp_mem &soccp_dtb_mem>;

		/* Inputs from SOCCP */
		interrupts-extended = <&intc GIC_SPI 167 IRQ_TYPE_EDGE_RISING>,
					<&soccp_smp2p_in 0 0>,
					<&soccp_smp2p_in 1 0>,
					<&soccp_smp2p_in 3 0>,
					<&soccp_smp2p_in 2 0>,
					<&soccp_smp2p_in 9 0>,
					<&soccp_smp2p_in 10 0>;

		interrupt-names = "wdog",
				"fatal",
				"ready",
				"stop-ack",
				"handover",
				"pong",
				"wake-ack";

		/* Outputs to soccp */
		qcom,smem-states = <&soccp_smp2p_out 0>, <&soccp_smp2p_out 10>, <&soccp_smp2p_out 9>, <&soccp_smp2p_out 8>;
		qcom,smem-state-names = "stop", "wakeup", "sleep", "ping";

		glink-edge {
			qcom,remote-pid = <19>;
			transport = "smem";
			mboxes = <&ipcc_mproc IPCC_MPROC_SOCCP
				  IPCC_MPROC_SIGNAL_GLINK_QMP>;
			mbox-names = "soccp_smem";
			interrupt-parent = <&ipcc_mproc>;
			interrupts = <IPCC_MPROC_SOCCP
				      IPCC_MPROC_SIGNAL_GLINK_QMP
				      IRQ_TYPE_EDGE_RISING>;

			label = "soccp";
			qcom,glink-label = "soccp";

			qcom,soccp_qrtr {
				qcom,glink-channels = "IPCRTR";
				qcom,intents = <0x800  5
						0x2000 3
						0x4400 2>;
			};

			qcom,pmic_glink_rpmsg {
				qcom,glink-channels = "PMIC_RTR_SOCCP_APPS";
			};

			qcom,pmic_glink_log_rpmsg {
				qcom,glink-channels = "PMIC_LOGS_SOCCP_APPS";
				qcom,intents = <0x800 5
						0xc00 3
						0x2000 1>;
			};
		};
	};

	thermal_zones: thermal-zones {};

	pmic_arbiter: arbiter@c400000 {
		compatible = "qcom,canoe-spmi-pmic-arb";
		reg = <0x0 0xc400000 0x0 0x3000>,
		      <0x0 0xc900000 0x0 0x400000>,
		      <0x0 0xc4c0000 0x0 0x400000>,
		      <0x0 0xc403000 0x0 0x8000>;
		reg-names = "core", "chnls", "obsrvr", "chnl_map";
		#address-cells = <2>;
		#size-cells = <2>;
		ranges;
		qcom,channel = <0>;
		qcom,ee = <0>;

		spmi0_bus: spmi@c426000 {
			reg = <0x0 0xc426000 0x0 0x4000>,
			      <0x0 0xc8c0000 0x0 0x10000>,
			      <0x0 0xc42a000 0x0 0x8000>;
			reg-names = "cnfg", "intr", "chnl_owner";
			interrupts-extended = <&pdc 1 IRQ_TYPE_LEVEL_HIGH>;
			interrupt-names = "periph_irq";
			interrupt-controller;
			#interrupt-cells = <4>;
			#address-cells = <2>;
			#size-cells = <0>;
		};

		spmi1_bus: spmi@c437000 {
			reg = <0x0 0xc437000 0x0 0x4000>,
			      <0x0 0xc8d0000 0x0 0x10000>,
			      <0x0 0xc43b000 0x0 0x8000>;
			reg-names = "cnfg", "intr", "chnl_owner";
			interrupts-extended = <&pdc 3 IRQ_TYPE_LEVEL_HIGH>;
			interrupt-names = "periph_irq";
			interrupt-controller;
			#interrupt-cells = <4>;
			#address-cells = <2>;
			#size-cells = <0>;
		};
	};

	pmic-arb-debug@11314000 {
		compatible = "qcom,spmi-pmic-arb-debug-v8";
		reg = <0x0 0x11314000 0x0 0x64>,
		      <0x0 0x221c8780 0x0 0x4>;
		reg-names = "core", "fuse";
		clocks = <&aoss_qmp>;
		clock-names = "core_clk";
		qcom,fuse-enable-bit = <14>;
		#address-cells = <1>;
		#size-cells = <0>;
		depends-on-supply = <&pmic_arbiter>;

		spmi0_debug_bus: spmi@0 {
			reg = <0>;
			#address-cells = <2>;
			#size-cells = <0>;

			pmk8850@0 {
				compatible = "qcom,spmi-pmic";
				reg = <0 SPMI_USID>;
				#address-cells = <2>;
				#size-cells = <0>;
				qcom,can-sleep;
			};

			pm8550@1 {
				compatible = "qcom,spmi-pmic";
				reg = <1 SPMI_USID>;
				#address-cells = <2>;
				#size-cells = <0>;
				qcom,can-sleep;
			};

			pmg1110@2 {
				compatible = "qcom,spmi-pmic";
				reg = <2 SPMI_USID>;
				#address-cells = <2>;
				#size-cells = <0>;
				qcom,can-sleep;
			};

			pm8550ve@3 {
				compatible = "qcom,spmi-pmic";
				reg = <3 SPMI_USID>;
				#address-cells = <2>;
				#size-cells = <0>;
				qcom,can-sleep;
			};

			pm8550ve@5 {
				compatible = "qcom,spmi-pmic";
				reg = <5 SPMI_USID>;
				#address-cells = <2>;
				#size-cells = <0>;
				qcom,can-sleep;
			};

			pm8550ve@6 {
				compatible = "qcom,spmi-pmic";
				reg = <6 SPMI_USID>;
				#address-cells = <2>;
				#size-cells = <0>;
				qcom,can-sleep;
			};

			pm8550ve@8 {
				compatible = "qcom,spmi-pmic";
				reg = <8 SPMI_USID>;
				#address-cells = <2>;
				#size-cells = <0>;
				qcom,can-sleep;
			};

			pmg1110@9 {
				compatible = "qcom,spmi-pmic";
				reg = <9 SPMI_USID>;
				#address-cells = <2>;
				#size-cells = <0>;
				qcom,can-sleep;
			};

			pmr735d@a {
				compatible = "qcom,spmi-pmic";
				reg = <10 SPMI_USID>;
				#address-cells = <2>;
				#size-cells = <0>;
				qcom,can-sleep;
			};

			pmg1110@b {
				compatible = "qcom,spmi-pmic";
				reg = <11 SPMI_USID>;
				#address-cells = <2>;
				#size-cells = <0>;
				qcom,can-sleep;
			};

			pm8010@c {
				compatible = "qcom,spmi-pmic";
				reg = <12 SPMI_USID>;
				#address-cells = <2>;
				#size-cells = <0>;
				qcom,can-sleep;
			};

			pm8010@d {
				compatible = "qcom,spmi-pmic";
				reg = <13 SPMI_USID>;
				#address-cells = <2>;
				#size-cells = <0>;
				qcom,can-sleep;
			};
		};
	};

	qcom,qrtr-gunyah-oemvm {
		compatible = "qcom,qrtr-gunyah";
		qcom,master;
		gunyah-label = <0x108>;
		peer-name = <4>;
	};

	pmic-glink {
		compatible = "qcom,qti-pmic-glink";
		qcom,pmic-glink-channel = "PMIC_RTR_SOCCP_APPS";
		depends-on-supply = <&ipcc_mproc>;
		qcom,subsys-name = "soccp";

		battery_charger: battery-charger {
			compatible = "qcom,battery-charger";
		};

		ucsi: ucsi-glink {
			compatible = "qcom,ucsi-glink";
		};

		altmode: altmode-glink {
			compatible = "qcom,altmode-glink";
			#altmode-cells = <1>;
		};
	};

	pmic-glink-log {
		compatible = "qcom,qti-pmic-glink";
		qcom,pmic-glink-channel = "PMIC_LOGS_SOCCP_APPS";

		battery-debug {
			compatible = "qcom,battery-debug";
		};

		charger-ulog-glink {
			compatible = "qcom,charger-ulog-glink";
		};

		pmic_glink_debug: pmic-glink-debug {
			compatible = "qcom,pmic-glink-debug";
			#address-cells = <1>;
			#size-cells = <0>;
			depends-on-supply = <&spmi1_bus>;
		};

		pmic_glink_adc: glink-adc {
			compatible = "qcom,glink-adc";
			#address-cells = <1>;
			#size-cells = <0>;
			#io-channel-cells = <1>;
			status = "disabled";
		};
	};

	qcom,glinkpkt {
		compatible = "qcom,glinkpkt";

		qcom,glinkpkt-at-mdm0 {
			qcom,glinkpkt-edge = "mpss";
			qcom,glinkpkt-ch-name = "DS";
			qcom,glinkpkt-dev-name = "at_mdm0";
		};

		qcom,glinkpkt-apr-apps2 {
			qcom,glinkpkt-edge = "adsp";
			qcom,glinkpkt-ch-name = "apr_apps2";
			qcom,glinkpkt-dev-name = "apr_apps2";
		};

		qcom,glinkpkt-data40-cntl {
			qcom,glinkpkt-edge = "mpss";
			qcom,glinkpkt-ch-name = "DATA40_CNTL";
			qcom,glinkpkt-dev-name = "smdcntl8";
		};

		qcom,glinkpkt-data1 {
			qcom,glinkpkt-edge = "mpss";
			qcom,glinkpkt-ch-name = "DATA1";
			qcom,glinkpkt-dev-name = "smd7";
		};

		qcom,glinkpkt-data4 {
			qcom,glinkpkt-edge = "mpss";
			qcom,glinkpkt-ch-name = "DATA4";
			qcom,glinkpkt-dev-name = "smd8";
		};

		qcom,glinkpkt-data11 {
			qcom,glinkpkt-edge = "mpss";
			qcom,glinkpkt-ch-name = "DATA11";
			qcom,glinkpkt-dev-name = "smd11";
		};

		qcom,glinkpkt-qmc-dma {
			qcom,glinkpkt-edge = "mpss";
			qcom,glinkpkt-ch-name = "QMC_DMA_LINE";
			qcom,glinkpkt-dev-name = "qmc_dma";
			qcom,glinkpkt-enable-ch-close;
		};

		qcom,glinkpkt-qmc-cma {
			qcom,glinkpkt-edge = "mpss";
			qcom,glinkpkt-ch-name = "QMC_CMA_LINE";
			qcom,glinkpkt-dev-name = "qmc_cma";
			qcom,glinkpkt-enable-ch-close;
		};

		qcom,glinkpkt-ims-sub-1 {
			qcom,glinkpkt-edge = "mpss";
			qcom,glinkpkt-ch-name = "Ims_dc_sub1";
			qcom,glinkpkt-dev-name = "ims_dc_sub1";
			qcom,glinkpkt-enable-ch-close;
		};

		qcom,glinkpkt-ims-sub-2 {
			qcom,glinkpkt-edge = "mpss";
			qcom,glinkpkt-ch-name = "Ims_dc_sub2";
			qcom,glinkpkt-dev-name = "ims_dc_sub2";
			qcom,glinkpkt-enable-ch-close;
		};

		qcom,glinkpkt-xpan_control {
			qcom,glinkpkt-edge = "adsp";
			qcom,glinkpkt-ch-name = "bt_cp_ctrl";
			qcom,glinkpkt-dev-name = "bt_cp_ctrl";
		};
	};
};

#include "alor-debug.dtsi"
#include "alor-coresight.dtsi"
#include "alor-pinctrl.dtsi"
#include "alor-regulators.dtsi"
#include "alor-qupv3.dtsi"
#include "alor-usb.dtsi"
#include "alor-walt.dtsi"
#include "alor-thermal.dtsi"

&qupv3_se7_2uart {
	status = "ok";
};

&qupv3_se3_i2c {
	status = "ok";
	wcd_usbss: wcd939x_i2c@e {
		status = "disabled";
		compatible = "qcom,wcd939x-i2c";
		reg = <0xe>;
		vdd-usb-cp-supply = <&L15B>;
	};
};

#include "ipcc-test-canoe.dtsi"
#include "msm-rdbg.dtsi"
/delete-node/ &ipcc_self_ping_adsp;
/delete-node/ &ipcc_self_ping_cdsp;
/delete-node/ &ipcc_self_ping_slpi;
